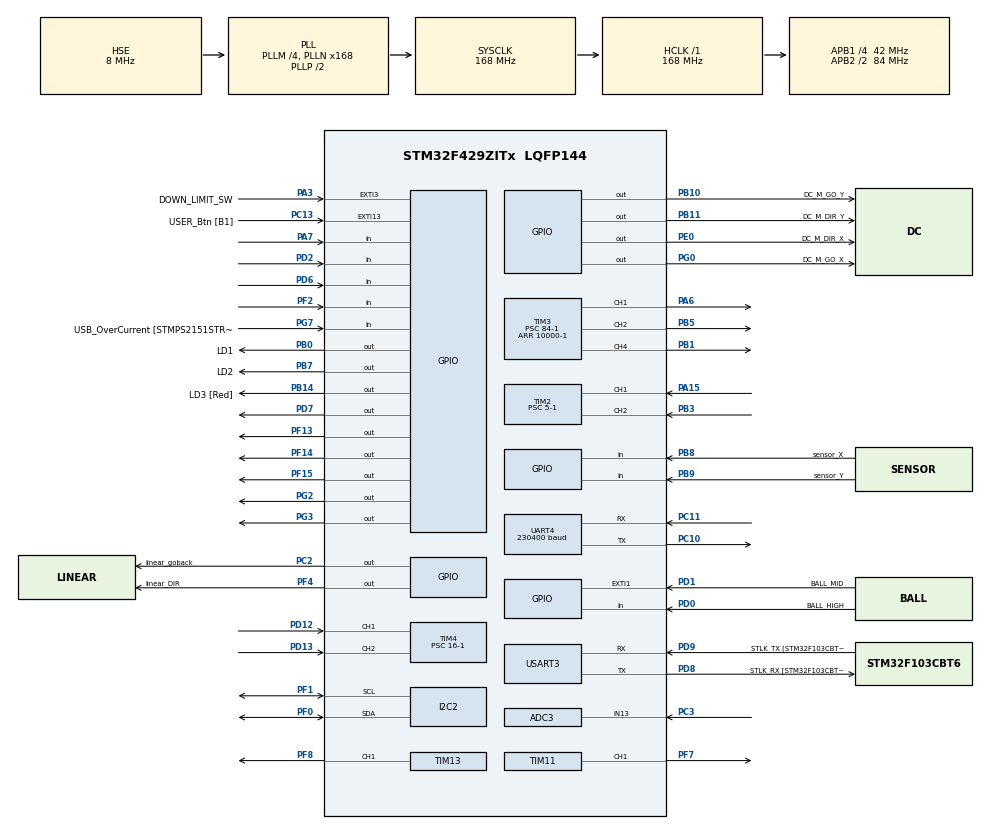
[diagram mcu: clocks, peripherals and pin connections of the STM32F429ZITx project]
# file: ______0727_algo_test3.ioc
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ADC3.Channel-3\#ChannelRegularConversion=ADC_CHANNEL_13
ADC3.Channel-4\#ChannelRegularConversion=ADC_CHANNEL_10
ADC3.Channel-5\#ChannelRegularConversion=ADC_CHANNEL_11
ADC3.ContinuousConvMode=DISABLE
ADC3.DMAContinuousRequests=ENABLE
ADC3.DiscontinuousConvMode=ENABLE
ADC3.ExternalTrigConv=ADC_EXTERNALTRIGCONV_T8_TRGO
ADC3.NbrOfConversion=3
ADC3.NbrOfConversionFlag=1
ADC3.NbrOfDiscConversion=3
ADC3.Rank-3\#ChannelRegularConversion=1
ADC3.Rank-4\#ChannelRegularConversion=2
ADC3.Rank-5\#ChannelRegularConversion=3
ADC3.Resolution=ADC_RESOLUTION_12B
ADC3.SamplingTime-3\#ChannelRegularConversion=ADC_SAMPLETIME_480CYCLES
ADC3.SamplingTime-4\#ChannelRegularConversion=ADC_SAMPLETIME_480CYCLES
ADC3.SamplingTime-5\#ChannelRegularConversion=ADC_SAMPLETIME_480CYCLES
ADC3.ScanConvMode=ENABLE
Dma.ADC3.0.Direction=DMA_PERIPH_TO_MEMORY
Dma.ADC3.0.FIFOMode=DMA_FIFOMODE_DISABLE
Dma.ADC3.0.Instance=DMA2_Stream1
Dma.ADC3.0.MemDataAlignment=DMA_MDATAALIGN_HALFWORD
Dma.ADC3.0.MemInc=DMA_MINC_ENABLE
Dma.ADC3.0.Mode=DMA_CIRCULAR
Dma.ADC3.0.PeriphDataAlignment=DMA_PDATAALIGN_HALFWORD
Dma.ADC3.0.PeriphInc=DMA_PINC_DISABLE
Dma.ADC3.0.Priority=DMA_PRIORITY_LOW
Dma.Request0=ADC3
Mcu.Family=STM32F4
Mcu.Name=STM32F429ZITx
Mcu.Package=LQFP144
NVIC.ADC_IRQn=true\:14\:0\:true\:false\:true\:true\:true\:true
NVIC.DMA2_Stream1_IRQn=true\:0\:0\:false\:false\:true\:false\:true\:true
NVIC.EXTI15_10_IRQn=true\:0\:0\:false\:false\:true\:true\:true\:true
NVIC.EXTI1_IRQn=true\:2\:0\:true\:false\:true\:true\:true\:true
NVIC.EXTI3_IRQn=true\:0\:0\:false\:true\:true\:1\:true\:true\:true
NVIC.PriorityGroup=NVIC_PRIORITYGROUP_4
NVIC.TIM1_BRK_TIM9_IRQn=true\:0\:0\:true\:false\:true\:true\:true\:true
NVIC.TIM1_TRG_COM_TIM11_IRQn=true\:0\:0\:true\:false\:true\:true\:true\:true
NVIC.TIM1_UP_TIM10_IRQn=true\:0\:0\:true\:false\:true\:true\:true\:true
NVIC.TIM5_IRQn=true\:0\:0\:true\:false\:true\:true\:true\:true
NVIC.TIM6_DAC_IRQn=true\:0\:0\:true\:false\:true\:true\:true\:true
NVIC.TIM7_IRQn=true\:0\:0\:true\:false\:true\:true\:true\:true
NVIC.TIM8_BRK_TIM12_IRQn=true\:0\:0\:true\:false\:true\:true\:true\:true
NVIC.TIM8_TRG_COM_TIM14_IRQn=true\:0\:0\:true\:false\:true\:true\:true\:true
NVIC.TIM8_UP_TIM13_IRQn=true\:0\:0\:true\:false\:true\:true\:true\:true
NVIC.UART4_IRQn=true\:15\:0\:true\:false\:true\:true\:true\:true
NVIC.USART3_IRQn=true\:15\:0\:true\:false\:true\:true\:true\:true
PA13.GPIO_Label=TMS
PA13.Mode=Serial_Wire
PA13.Signal=SYS_JTMS-SWDIO
PA14.GPIO_Label=TCK
PA14.Mode=Serial_Wire
PA14.Signal=SYS_JTCK-SWCLK
PA15.GPIO_Speed=GPIO_SPEED_FREQ_VERY_HIGH
PA15.Signal=S_TIM2_CH1_ETR
PA3.GPIO_Label=DOWN_LIMIT_SW
PA3.GPIO_ModeDefaultEXTI=GPIO_MODE_IT_FALLING
PA3.Signal=GPXTI3
PA6.GPIO_Speed=GPIO_SPEED_FREQ_VERY_HIGH
PA6.Signal=S_TIM3_CH1
PA7.Signal=GPIO_Input
PB0.GPIO_Label=LD1
PB0.Signal=GPIO_Output
PB1.GPIO_Speed=GPIO_SPEED_FREQ_VERY_HIGH
PB1.Signal=S_TIM3_CH4
PB10.GPIO_Label=DC_M_GO_Y
PB10.GPIO_Speed=GPIO_SPEED_FREQ_LOW
PB10.Signal=GPIO_Output
PB11.GPIO_Label=DC_M_DIR_Y
PB11.GPIO_Speed=GPIO_SPEED_FREQ_VERY_HIGH
PB11.Signal=GPIO_Output
PB14.GPIO_Label=LD3 [Red]
PB14.Signal=GPIO_Output
PB3.GPIO_Speed=GPIO_SPEED_FREQ_VERY_HIGH
PB3.Signal=S_TIM2_CH2
PB5.GPIO_Speed=GPIO_SPEED_FREQ_VERY_HIGH
PB5.Signal=S_TIM3_CH2
PB7.GPIO_Label=LD2
PB7.Signal=GPIO_Output
PB8.GPIO_Label=sensor_X
PB8.Signal=GPIO_Input
PB9.GPIO_Label=sensor_Y
PB9.Signal=GPIO_Input
PC10.Mode=Asynchronous
PC10.Signal=UART4_TX
PC11.Mode=Asynchronous
PC11.Signal=UART4_RX
PC13.GPIO_Label=USER_Btn [B1]
PC13.Signal=GPXTI13
PC14/OSC32_IN.Mode=LSE-External-Oscillator
PC14/OSC32_IN.Signal=RCC_OSC32_IN
PC15/OSC32_OUT.Mode=LSE-External-Oscillator
PC15/OSC32_OUT.Signal=RCC_OSC32_OUT
PC2.GPIO_Label=linear_goback
PC2.Signal=GPIO_Output
PC3.Signal=ADCx_IN13
PD0.GPIO_Label=BALL_HIGH
PD0.Signal=GPIO_Input
PD1.GPIO_Label=BALL_MID
PD1.GPIO_ModeDefaultEXTI=GPIO_MODE_IT_FALLING
PD1.Signal=GPXTI1
PD12.GPIO_Speed=GPIO_SPEED_FREQ_VERY_HIGH
PD12.Signal=S_TIM4_CH1
PD13.GPIO_Speed=GPIO_SPEED_FREQ_VERY_HIGH
PD13.Signal=S_TIM4_CH2
PD2.Signal=GPIO_Input
PD6.Signal=GPIO_Input
PD7.Signal=GPIO_Output
PD8.GPIO_Label=STLK_RX [STM32F103CBT6_PA3]
PD8.Mode=Asynchronous
PD8.Signal=USART3_TX
PD9.GPIO_Label=STLK_TX [STM32F103CBT6_PA2]
PD9.Mode=Asynchronous
PD9.Signal=USART3_RX
PE0.GPIO_Label=DC_M_DIR_X
PE0.GPIO_Speed=GPIO_SPEED_FREQ_VERY_HIGH
PE0.Signal=GPIO_Output
PF0.Mode=I2C
PF0.Signal=I2C2_SDA
PF1.Mode=I2C
PF1.Signal=I2C2_SCL
PF13.Signal=GPIO_Output
PF14.Signal=GPIO_Output
PF15.Signal=GPIO_Output
PF2.Signal=GPIO_Input
PF4.GPIO_Label=linear_DIR
PF4.Signal=GPIO_Output
PF7.GPIO_Speed=GPIO_SPEED_FREQ_VERY_HIGH
PF7.Signal=S_TIM11_CH1
PF8.GPIO_Speed=GPIO_SPEED_FREQ_VERY_HIGH
PF8.Signal=S_TIM13_CH1
PG0.GPIO_Label=DC_M_GO_X
PG0.GPIO_Speed=GPIO_SPEED_FREQ_LOW
PG0.Signal=GPIO_Output
PG2.Signal=GPIO_Output
PG3.Signal=GPIO_Output
PG7.GPIO_Label=USB_OverCurrent [STMPS2151STR_FAULT]
PG7.Signal=GPIO_Input
PH0/OSC_IN.GPIO_Label=MCO [STM32F103CBT6_PA8]
PH0/OSC_IN.Mode=HSE-External-Clock-Source
PH0/OSC_IN.Signal=RCC_OSC_IN
PH1/OSC_OUT.Mode=HSE-External-Clock-Source
PH1/OSC_OUT.Signal=RCC_OSC_OUT
ProjectManager.HeapSize=0x200
ProjectManager.StackSize=0x400
ProjectManager.TargetToolchain=STM32CubeIDE
RCC.48MHZClocksFreq_Value=48000000
RCC.AHBFreq_Value=168000000
RCC.APB1CLKDivider=RCC_HCLK_DIV4
RCC.APB1Freq_Value=42000000
RCC.APB1TimFreq_Value=84000000
RCC.APB2CLKDivider=RCC_HCLK_DIV2
RCC.APB2Freq_Value=84000000
RCC.APB2TimCLKDivider=2
RCC.APB2TimFreq_Value=168000000
RCC.CortexFreq_Value=168000000
RCC.HCLKFreq_Value=168000000
RCC.HSE_VALUE=8000000
RCC.HSI_VALUE=16000000
RCC.PLLM=4
RCC.PLLMUL=RCC_PLL_MUL9
RCC.PLLN=168
RCC.PLLQ=7
RCC.PLLSourceVirtual=RCC_PLLSOURCE_HSE
RCC.PRESCALERUSB=RCC_USBCLKSOURCE_PLL_DIV1_5
RCC.SYSCLKFreq_VALUE=168000000
RCC.SYSCLKSource=RCC_SYSCLKSOURCE_PLLCLK
RCC.SYSCLKSourceVirtual=RCC_SYSCLKSOURCE_PLLCLK
RCC.USBFreq_Value=48000000
RCC.VCOOutputFreq_Value=336000000
SH.ADCx_IN13.0=ADC3_IN13,IN13
SH.S_TIM11_CH1.0=TIM11_CH1,Output Compare1 CH1
SH.S_TIM13_CH1.0=TIM13_CH1,Output Compare1 CH1
SH.S_TIM2_CH1_ETR.0=TIM2_CH1,Encoder_Interface
SH.S_TIM2_CH2.0=TIM2_CH2,Encoder_Interface
SH.S_TIM3_CH1.0=TIM3_CH1,PWM Generation1 CH1
SH.S_TIM3_CH2.0=TIM3_CH2,PWM Generation2 CH2
SH.S_TIM3_CH4.0=TIM3_CH4,PWM Generation4 CH4
SH.S_TIM4_CH1.0=TIM4_CH1,Encoder_Interface
SH.S_TIM4_CH2.0=TIM4_CH2,Encoder_Interface
TIM10.Period=1000-1
TIM10.Prescaler=16800-1
TIM11.AutoReloadPreload=TIM_AUTORELOAD_PRELOAD_ENABLE
TIM11.Channel=TIM_CHANNEL_1
TIM11.OCMode_1=TIM_OCMODE_TOGGLE
TIM11.Period=800-1
TIM11.Prescaler=168-1
TIM11.Pulse=50
TIM12.Period=1000-1
TIM12.Prescaler=8400-1
TIM13.AutoReloadPreload=TIM_AUTORELOAD_PRELOAD_ENABLE
TIM13.Channel=TIM_CHANNEL_1
TIM13.OC1Preload=ENABLE
TIM13.OCMode_1=TIM_OCMODE_TOGGLE
TIM13.Period=800-1
TIM13.Prescaler=84-1
TIM13.Pulse=130
TIM14.Period=10000-1
TIM14.Prescaler=84-1
TIM2.EncoderMode=TIM_ENCODERMODE_TI12
TIM2.Period=0xffffffff
TIM2.Prescaler=5-1
TIM3.Channel-PWM\ Generation1\ CH1=TIM_CHANNEL_1
TIM3.Channel-PWM\ Generation2\ CH2=TIM_CHANNEL_2
TIM3.Channel-PWM\ Generation4\ CH4=TIM_CHANNEL_4
TIM3.Period=10000-1
TIM3.Prescaler=84-1
TIM3.Pulse-PWM\ Generation1\ CH1=600
TIM3.Pulse-PWM\ Generation2\ CH2=600
TIM3.Pulse-PWM\ Generation4\ CH4=0
TIM4.EncoderMode=TIM_ENCODERMODE_TI12
TIM4.Period=0xFFFF-1
TIM4.Prescaler=16-1
TIM5.Period=10000-1
TIM5.Prescaler=84-1
TIM6.Period=1000-1
TIM6.Prescaler=84-1
TIM7.Period=100-1
TIM7.Prescaler=84-1
TIM8.Channel-Output\ Compare4\ No\ Output=TIM_CHANNEL_4
TIM8.Period=300-1
TIM8.Prescaler=84-1
TIM8.Pulse-Output\ Compare4\ No\ Output=2000
TIM8.TIM_MasterOutputTrigger=TIM_TRGO_UPDATE
TIM9.Period=1000-1
TIM9.Prescaler=16800-1
UART4.BaudRate=230400
UART4.Parity=PARITY_EVEN
UART4.VirtualMode=Asynchronous
USART3.VirtualMode=VM_ASYNC
VP_TIM10_VS_ClockSourceINT.Mode=Enable_Timer
VP_TIM11_VS_ClockSourceINT.Mode=Enable_Timer
VP_TIM12_VS_ClockSourceINT.Mode=Internal
VP_TIM13_VS_ClockSourceINT.Mode=Enable_Timer
VP_TIM14_VS_ClockSourceINT.Mode=Enable_Timer
VP_TIM3_VS_ClockSourceINT.Mode=Internal
VP_TIM5_VS_ClockSourceINT.Mode=Internal
VP_TIM6_VS_ClockSourceINT.Mode=Enable_Timer
VP_TIM7_VS_ClockSourceINT.Mode=Enable_Timer
VP_TIM8_VS_ClockSourceINT.Mode=Internal
VP_TIM8_VS_no_output4.Mode=Output Compare4 No Output
VP_TIM9_VS_ClockSourceINT.Mode=Internal
board=NUCLEO-F429ZI

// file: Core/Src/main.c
/* USER CODE BEGIN Header */
/**
 ******************************************************************************
 * @file           : main.c
 * @brief          : Main program body
 ******************************************************************************
 * @attention
 *
 * Copyright (c) 2024 STMicroelectronics.
 * All rights reserved.
 *
 * This software is licensed under terms that can be found in the LICENSE file
 * in the root directory of this software component.
 * If no LICENSE file comes with this software, it is provided AS-IS.
 *
 ******************************************************************************
 */
/* USER CODE END Header */
#include "main.h"

/* USER CODE BEGIN Includes */
#include "pid.h"
#include "sensor.h"
#include "step.h"
#include "linear.h"
#include "pp.h"
#include "mpu6050.h"
#include "queue.h"
//시뮬링크
#include "rtwtypes.h"
#include "downpart_accel.h"
//

uint8_t key_value;

uint8_t data;

uint32_t encoder_count_x = 1000000;
uint16_t encoder_count_y = 30000;
extern uint32_t tim4_encoder_overflow;

uint16_t ADC3_value[3];

extern uint8_t tim6_flag;
extern uint8_t tim14_flag;
extern uint8_t tim5_flag;
/* USER CODE END Includes */

/* USER CODE BEGIN PM */
extern uint16_t shaft_pulse_cycle;
extern uint16_t ball_screw_pulse_cycle;
/* USER CODE END PM */

ADC_HandleTypeDef hadc3;
DMA_HandleTypeDef hdma_adc3;

I2C_HandleTypeDef hi2c2;

TIM_HandleTypeDef htim2;
TIM_HandleTypeDef htim3;
TIM_HandleTypeDef htim4;
TIM_HandleTypeDef htim5;
TIM_HandleTypeDef htim6;
TIM_HandleTypeDef htim7;
TIM_HandleTypeDef htim8;
TIM_HandleTypeDef htim9;
TIM_HandleTypeDef htim10;
TIM_HandleTypeDef htim11;
TIM_HandleTypeDef htim12;
TIM_HandleTypeDef htim13;
TIM_HandleTypeDef htim14;

UART_HandleTypeDef huart4;
UART_HandleTypeDef huart3;

void SystemClock_Config(void);
static void MX_GPIO_Init(void);
static void MX_DMA_Init(void);
static void MX_USART3_UART_Init(void);
static void MX_TIM3_Init(void);
static void MX_TIM14_Init(void);
static void MX_UART4_Init(void);
static void MX_TIM2_Init(void);
static void MX_TIM8_Init(void);
static void MX_TIM6_Init(void);
static void MX_TIM13_Init(void);
static void MX_ADC3_Init(void);
static void MX_TIM12_Init(void);
static void MX_TIM11_Init(void);
static void MX_TIM4_Init(void);
static void MX_TIM7_Init(void);
static void MX_TIM5_Init(void);
static void MX_I2C2_Init(void);
static void MX_TIM9_Init(void);
static void MX_TIM10_Init(void);
static void MX_NVIC_Init(void);
/* USER CODE BEGIN PFP */
bool accel_flag;

//struct {
//	bool target_2_1;
//	bool target_3_1;
//	bool target_1_2;
//	bool target_2_2;
//	bool target_3_2;
//
//	bool box_pickup;
//	bool Box_dropoff;
//} Manual_mode = { FALSE, FALSE, FALSE };
struct Manual Manual_mode = { FALSE, FALSE, FALSE, FALSE, FALSE, FALSE, FALSE};

struct flag Finish_flag = { FALSE, FALSE, FALSE, FALSE, FALSE, FALSE, FALSE, 0,
		0, FALSE, FALSE };

float targetS_X_GO = 53;
float targetS_X_BACK = 56.0;

float targetS_Y_GO = 49;
float targetS_Y_BACK = 48;

float targetS_X_GO2 = 98;
float targetS_X_BACK2 = 103;
//

float go_time = 1.25;
float back_time = 1.4;

/* USER CODE END PFP */

/* USER CODE BEGIN 0 */
bool photo_X_go = FALSE;
bool photo_X_back = FALSE;
bool photo_Y_go = FALSE;
bool photo_Y_back = FALSE;

int pickup_run;
int dropoff_run;

extern int pathLength;

cell path[CELL_DOMAIN_MAX];

extern float maxV;
extern float fallingN;
extern float fallingN_;
extern float raisingN;
extern float staticN;
extern float orderN;
extern uint16_t i_v_t_count;

uint8_t target_1_2_flag = 0;
uint8_t target_2_1_flag = 0;
uint8_t target_3_1_flag = 0;
uint8_t target_2_2_flag = 0;
uint8_t target_3_2_flag = 0;
uint8_t box_pickup_flag = 0;
uint8_t box_dropoff_flag = 0;
void FALSE_Init() {
	Finish_flag.x_go = FALSE;
	Finish_flag.x_back = FALSE;
	Finish_flag.y_go = FALSE;
	Finish_flag.y_back = FALSE;
	Finish_flag.ball_high = FALSE;
	Finish_flag.ball_mid = FALSE;
	Finish_flag.ball_low = FALSE;
	Finish_flag.downpart_high = FALSE;
	Finish_flag.downpart_low = FALSE;
	Finish_flag.linear_go = FALSE;
	Finish_flag.linear_back = FALSE;

	target_1_2_flag = 0;
	target_2_1_flag = 0;
	target_3_1_flag = 0;
	target_2_2_flag = 0;
	target_3_2_flag = 0;
	box_pickup_flag = 0;
	box_dropoff_flag = 0;

	pickup_run=0;
	dropoff_run= 0;
	Manual_mode.box_pickup = FALSE;
	Manual_mode.Box_dropoff = FALSE;
}
uint32_t downpart_step_1_floor = 8100; //
uint32_t downpart_step_2_floor = 6600;
uint32_t downpart_step_3_floor = 4500;  //예상
uint8_t box_floor;

int box_floor_test_pick = 1;
int box_floor_test_drop = 1;

//박스 적재 동작 : 다운파트 하강, 리니어 전진, 다운파트 상승

uint8_t box_floor;  //테스트용도
uint32_t downpart_step_floor;

void Box_pickup(uint8_t floor) {
	HAL_TIM_Encoder_Stop(&htim2, TIM_CHANNEL_ALL);
	HAL_TIM_Encoder_Stop(&htim4, TIM_CHANNEL_ALL);

	HAL_TIM_PWM_Stop(&htim3, TIM_CHANNEL_1);
	HAL_TIM_PWM_Stop(&htim3, TIM_CHANNEL_2);

	TIM3->CCR1 = 0;
	TIM3->CCR2 = 0;
	pickup_run = 1;

	box_floor = floor;

	if (floor == 1)
		downpart_step_floor = downpart_step_1_floor;
	else if (floor == 2)
		downpart_step_floor = downpart_step_2_floor;
	else if (floor == 3)
		downpart_step_floor = downpart_step_3_floor;

//	if (Manual_mode.box_pickup == TRUE) {
	if (box_pickup_flag == 0) {

		down_part_DOWN_accel(downpart_step_floor);
		box_pickup_flag = 1;
	}

	if ((Finish_flag.downpart_low == TRUE) && (box_pickup_flag == 1)) {
		box_pickup_flag = 2;
		HAL_Delay(700 - 1);

		linear_motor_GO(go_time);
		Finish_flag.downpart_low = FALSE;
	}
	if ((Finish_flag.linear_go == TRUE) && (box_pickup_flag == 2)) {
		box_pickup_flag = 3;
		HAL_Delay(700 - 1);
		down_part_UP_accel(downpart_step_floor + 10000);
		Finish_flag.linear_go = FALSE;
	}
	if ((Finish_flag.downpart_high == TRUE) && (box_pickup_flag == 3)) {
		box_pickup_flag = 4;
		HAL_Delay(120 - 1);

		down_part_DOWN(130, shaft_pulse_cycle);
		Finish_flag.downpart_high = FALSE;
	}
	if(	Finish_flag.downpart_low == TRUE && box_pickup_flag ==4)
	{
		box_pickup_flag =5;
		HAL_Delay(700 - 1);
		Finish_flag.downpart_low = FALSE;
		Manual_mode.box_pickup = FALSE;
		pickup_run = 0;
	}
//	}
}

//박스 하역 동작 : 다운파트 하강, 리니어 후진, 다운파트 상승
void Box_dropoff(uint8_t floor) {
	HAL_TIM_Encoder_Stop(&htim2, TIM_CHANNEL_ALL);
	HAL_TIM_Encoder_Stop(&htim4, TIM_CHANNEL_ALL);

	HAL_TIM_PWM_Stop(&htim3, TIM_CHANNEL_1);
	HAL_TIM_PWM_Stop(&htim3, TIM_CHANNEL_2);

	TIM3->CCR1 = 0;
	TIM3->CCR2 = 0;

	dropoff_run = 1;

	box_floor = floor;

	if (floor == 1)
		downpart_step_floor = downpart_step_1_floor;
	else if (floor == 2)
		downpart_step_floor = downpart_step_2_floor;
	else if (floor == 3)
		downpart_step_floor = downpart_step_3_floor;

	//if (Manual_mode.Box_dropoff == TRUE) {
	if (box_dropoff_flag == 0) {
		down_part_DOWN_accel(downpart_step_floor);
		box_dropoff_flag = 1;
	}

	if ((Finish_flag.downpart_low == TRUE) && (box_dropoff_flag == 1)) {
		box_dropoff_flag = 2;
		HAL_Delay(700 - 1);

		linear_motor_BACK(back_time);
		Finish_flag.downpart_low = FALSE;
	}
	if ((Finish_flag.linear_back == TRUE) && (box_dropoff_flag == 2)) {
		box_dropoff_flag = 3;
		HAL_Delay(200 - 1);
		down_part_UP_accel(downpart_step_floor + 10000);
		Finish_flag.linear_back = FALSE;
	}
	if ((Finish_flag.downpart_high == TRUE) && (box_dropoff_flag == 3)) {
		box_dropoff_flag = 4;
		HAL_Delay(120 - 1);

		down_part_DOWN(130, shaft_pulse_cycle);
		Finish_flag.downpart_high = FALSE;
	}
	if(Finish_flag.downpart_low == TRUE && (box_dropoff_flag == 4))
	{
		box_dropoff_flag =5;
		HAL_Delay(700 - 1);
		Finish_flag.downpart_low = FALSE;
		Manual_mode.Box_dropoff = FALSE;
		dropoff_run = 0;
	}

//	}
}

//y축 1칸 왕복,  볼스크류 왕복  다운파트 통합본					                                     			1              2           3                         4              5                       6
void Manual_Mode_Y1(float row, float col, uint8_t floor_pick,
		uint8_t floor_drop) { //볼스크류 하상 먼저 >> y 전진, 다운파트 하강, 리니어 전진, 다운파트 상승, y 후진, 다운파트 하강, 리니어 후진 ,다운파트 상승, 볼스크류 상승
//																	      -------------------------------        ------------------------------
	if (Manual_mode.target_1_2 == TRUE) {

		if (target_1_2_flag == 0) {

			z_axis_DOWN(400 * 6 * 2 + 500, ball_screw_pulse_cycle);
			target_1_2_flag = 1;
		}

		if ((Finish_flag.ball_low == TRUE) && (target_1_2_flag == 1)) {
			target_1_2_flag = 2;
			HAL_Delay(700 - 1);
			v_t_graph_DIR_GO_Y(targetS_Y_GO);  //앞으로

			Finish_flag.ball_low = FALSE;
		}
		if ((Finish_flag.y_go == TRUE) && (target_1_2_flag == 2)) {
			target_1_2_flag = 3;
			HAL_Delay(2100 - 1);

			Manual_mode.box_pickup = TRUE;
			box_floor_test_pick = floor_pick;
			Finish_flag.y_go = FALSE;
		}
		if ((Manual_mode.box_pickup == FALSE) && (target_1_2_flag == 3)) {

			target_1_2_flag = 4;
			HAL_Delay(700 - 1);
			v_t_graph_DIR_BACK_Y(targetS_Y_BACK);

		}
		if ((Finish_flag.y_back == TRUE) && (target_1_2_flag == 4)) {
			target_1_2_flag = 5;
			HAL_Delay(700 - 1);
			//		down_part_DOWN_accel(downpart_step_1_floor);

			Manual_mode.Box_dropoff = TRUE;
			box_floor_test_drop = floor_drop;

			Finish_flag.y_back = FALSE;
		}

		if ((Manual_mode.Box_dropoff == FALSE) && (target_1_2_flag == 5)) {

			target_1_2_flag = 6;

			HAL_Delay(900 - 1);
			z_axis_UP(400 * 6 * 2, ball_screw_pulse_cycle);

			FALSE_Init();
			Manual_mode.target_1_2 = FALSE;
		}
	}
}

//(2,1)  (3,1)    여기는 볼스크류 필요없음                         //1       2          3            4       5        6          7        8
void Manual_Mode_X1(float row, float col, uint8_t floor_pick,
		uint8_t floor_drop) { // x전진 , 다운파트 하강, 리니어 전진, 다운파트 상승, x후진, 다운파트 하강, 리니어 후진, 다운파트 상승 끝
	//				                 -----------------------------          ----------------------------
	if (Manual_mode.target_2_1 == TRUE) {

		if (target_2_1_flag == 0) {
			v_t_graph_DIR_GO_X(targetS_X_GO);  //앞으로

			target_2_1_flag = 1;
		}

		if ((Finish_flag.x_go == TRUE) && (target_2_1_flag == 1)) {
			target_2_1_flag = 2;
			HAL_Delay(2100 - 1);

			Manual_mode.box_pickup = TRUE;
			box_floor_test_pick = floor_pick;
			Finish_flag.x_go = FALSE;

		}

		if ((Manual_mode.box_pickup == FALSE) && (target_2_1_flag == 2)) {

			target_2_1_flag = 3;
			HAL_Delay(700 - 1);
			v_t_graph_DIR_BACK_X(targetS_X_BACK);

		}
		if ((Finish_flag.x_back == TRUE) && (target_2_1_flag == 3)) {
			target_2_1_flag = 4;
			HAL_Delay(700 - 1);

			Manual_mode.Box_dropoff = TRUE;
			box_floor_test_drop = floor_drop;

			Finish_flag.x_back = FALSE;
		}

		if ((Manual_mode.Box_dropoff == FALSE) && (target_2_1_flag == 4)) {
			target_2_1_flag = 5;

			FALSE_Init();
			Manual_mode.target_2_1 = FALSE;
		}
	}
}

//			 1                    2                   3              4
void Manual_Mode_X2(float row, float col, uint8_t floor_pick,
		uint8_t floor_drop) { // x전진 , 다운파트 하강, 리니어 전진, 다운파트 상승, x후진, 다운파트 하강, 리니어 후진, 다운파트 상승 끝
	//				                                                   -----------------------------          ----------------------------
	if (Manual_mode.target_3_1 == TRUE) {

		if (target_3_1_flag == 0) {
			v_t_graph_DIR_GO_X(targetS_X_GO2);  //앞으로

			target_3_1_flag = 1;
		}

		if ((Finish_flag.x_go == TRUE) && (target_3_1_flag == 1)) {
			target_3_1_flag = 2;
			HAL_Delay(2100 - 1);

			Manual_mode.box_pickup = TRUE;
			box_floor_test_pick = floor_pick;
			Finish_flag.x_go = FALSE;

		}

		if ((Manual_mode.box_pickup == FALSE) && (target_3_1_flag == 2)) {

			target_3_1_flag = 3;
			HAL_Delay(700 - 1);
			v_t_graph_DIR_BACK_X(targetS_X_BACK2);

		}
		if ((Finish_flag.x_back == TRUE) && (target_3_1_flag == 3)) {
			target_3_1_flag = 4;
			HAL_Delay(700 - 1);

			Manual_mode.Box_dropoff = TRUE;
			box_floor_test_drop = floor_drop;

			Finish_flag.x_back = FALSE;
		}

		if ((Manual_mode.Box_dropoff == FALSE) && (target_3_1_flag == 4)) {
			target_3_1_flag = 5;

			FALSE_Init();
			Manual_mode.target_3_1 = FALSE;
		}
	}
}

// x축 1칸 전진 ,볼스크류 2번 다운, y축 전진 , y축 후진 , 볼스크류 2번 업, x축 후진
//여기서 다운 파트 추가
//x 1칸 전진 , 볼스크류 다운, y축 전진 , 다운파트 하강, 리니어 전진, 다운파트 상승, y후진, 볼스크류 업, x후진, 다운파트 하상, 리니어 후진, 다운파트 상승
//                               ------------------------------                      --------------------------------
// 1              2         3                  4                    5       6     7          8
void Manual_Mode_X1Y1(float row, float col, uint8_t floor_pick,
		uint8_t floor_drop) {

	if (Manual_mode.target_2_2 == TRUE) {

		if (target_2_2_flag == 0) {
			v_t_graph_DIR_GO_X(targetS_X_GO);  // x 앞으로

			target_2_2_flag = 1;
		}

		if ((Finish_flag.x_go == TRUE) && (target_2_2_flag == 1)) {
			target_2_2_flag = 2;
			HAL_Delay(700 - 1);

			z_axis_DOWN(400 * 6 * 2 + 500, ball_screw_pulse_cycle); //볼스크류 2번 다운

			Finish_flag.x_go = FALSE;
		}
		if ((Finish_flag.ball_low == TRUE) && (target_2_2_flag == 2)) {
			target_2_2_flag = 3;
			HAL_Delay(700 - 1);
			v_t_graph_DIR_GO_Y(targetS_Y_GO); //					// y축 전진
			Finish_flag.ball_low = FALSE;
		}
		if ((Finish_flag.y_go == TRUE) && (target_2_2_flag == 3)) {
			target_2_2_flag = 4;
			HAL_Delay(3000 - 1);

			Manual_mode.box_pickup = TRUE;
			box_floor_test_pick = floor_pick;

			Finish_flag.y_go = FALSE;
		}
		if ((Manual_mode.box_pickup == FALSE) && (target_2_2_flag == 4)) {
			target_2_2_flag = 5;
			HAL_Delay(700 - 1);
			v_t_graph_DIR_BACK_Y(targetS_Y_BACK); //	y후진

			//Finish_flag.y_back = FALSE;
		}
		if ((Finish_flag.y_back == TRUE) && (target_2_2_flag == 5)) {
			target_2_2_flag = 6;
			HAL_Delay(700 - 1);

			z_axis_UP(400 * 6 * 2, ball_screw_pulse_cycle); //		    볼스크류 2번 업

			Finish_flag.y_back = FALSE;
		}
		if ((Finish_flag.ball_high == TRUE) && (target_2_2_flag == 6)) {
			target_2_2_flag = 7;
			HAL_Delay(700 - 1);
			v_t_graph_DIR_BACK_X(targetS_X_BACK); //
			Finish_flag.ball_high = FALSE;
		}
		if ((Finish_flag.x_back == TRUE) && (target_2_2_flag == 7)) {
			target_2_2_flag = 8;
			HAL_Delay(700 - 1);

			Manual_mode.Box_dropoff = TRUE;
			box_floor_test_drop = floor_drop;

			Finish_flag.x_back = FALSE;
		}
		if ((Manual_mode.Box_dropoff == FALSE) && (target_2_2_flag == 8)) {
			target_2_2_flag = 9;
			HAL_Delay(700 - 1);

			FALSE_Init();
			Manual_mode.target_2_2 = FALSE;
		}

	}
}

//x 1칸 전진 , 볼스크류 다운, y축 전진 , 다운파트 하강, 리니어 전진, 다운파트 상승, y후진, 볼스크류 업, x후진, 다운파트 하상, 리니어 후진, 다운파트 상승
//                               ------------------------------                      --------------------------------
// 1              2         3                  4                    5       6     7          8
void Manual_Mode_X2Y1(float row, float col, uint8_t floor_pick,
		uint8_t floor_drop) {

	if (Manual_mode.target_3_2 == TRUE) {

		if (target_3_2_flag == 0) {
			v_t_graph_DIR_GO_X(targetS_X_GO2);  // x 2칸 앞으로

			target_3_2_flag = 1;
		}

		if ((Finish_flag.x_go == TRUE) && (target_3_2_flag == 1)) {
			target_3_2_flag = 2;
			HAL_Delay(700 - 1);

			z_axis_DOWN(400 * 6 * 2 + 500, ball_screw_pulse_cycle); //볼스크류 2번 다운

			Finish_flag.x_go = FALSE;
		}
		if ((Finish_flag.ball_low == TRUE) && (target_3_2_flag == 2)) {
			target_3_2_flag = 3;
			HAL_Delay(700 - 1);
			v_t_graph_DIR_GO_Y(targetS_Y_GO); //					// y축 전진
			Finish_flag.ball_low = FALSE;
		}
		if ((Finish_flag.y_go == TRUE) && (target_3_2_flag == 3)) {
			target_3_2_flag = 4;
			HAL_Delay(2100 - 1);

			Manual_mode.box_pickup = TRUE;

			box_floor_test_pick = floor_pick;

			Finish_flag.y_go = FALSE;
		}
		if ((Manual_mode.box_pickup == FALSE) && (target_3_2_flag == 4)) {
			target_3_2_flag = 5;
			HAL_Delay(700 - 1);
			v_t_graph_DIR_BACK_Y(targetS_Y_BACK); //	y후진

			//Finish_flag.y_back = FALSE;
		}
		if ((Finish_flag.y_back == TRUE) && (target_3_2_flag == 5)) {
			target_3_2_flag = 6;
			HAL_Delay(700 - 1);

			z_axis_UP(400 * 6 * 2, ball_screw_pulse_cycle); //		    볼스크류 2번 업

			Finish_flag.y_back = FALSE;
		}
		if ((Finish_flag.ball_high == TRUE) && (target_3_2_flag == 6)) {
			target_3_2_flag = 7;
			HAL_Delay(700 - 1);
			v_t_graph_DIR_BACK_X(targetS_X_BACK2); //
			Finish_flag.ball_high = FALSE;
		}
		if ((Finish_flag.x_back == TRUE) && (target_3_2_flag == 7)) {
			target_3_2_flag = 8;
			HAL_Delay(700 - 1);

			Manual_mode.Box_dropoff = TRUE;
			box_floor_test_drop = floor_drop;

			Finish_flag.x_back = FALSE;
		}
		if ((Manual_mode.Box_dropoff == FALSE) && (target_3_2_flag == 8)) {
			target_3_2_flag = 9;
			HAL_Delay(700 - 1);

			FALSE_Init();
			Manual_mode.target_3_2 = FALSE;
		}

	}
}

int linear_init = 0;

char txData[] = "Hello, UART3!\r\n";
char rxData[100];

uint8_t rxByte;
volatile uint8_t rxIndex = 0;

#define DATA_SIZE 200

char segment[6];

char Rx_data[DATA_SIZE];
char Rx_buffer[2];  // 1글자씩 수신
int Transfer_finish = 0;  // 전송 완료 플래그

extern float RPM_X, RPM_Y;
extern int down_max_flag;

int plc;

int pik;

int rol = 0;

Queue str_q;
char pased_flag = '0';
char tmp;

bool paser_flag = FALSE;

void fillQueue(char *input) {
	int input_length = strlen(input);
	int i = 0;

	for (i = 0; i < input_length; i++) {
		enqueue(&str_q, input[i]);
	}
}
char cmd_[4];

char num;
/*
 void analyzer(char cmd[4], char num) {

 if (strcmp(&cmd[0], "mov") == 0) {
 //		mov++;

 HAL_Delay(2500);
 if (rol % 2==0)  //짝수: x방향  후진
 {
 if(num == '1')
 {
 v_t_graph_DIR_BACK_X(targetS_X_BACK);  // x 앞으로
 }
 else if(num == '2')
 {
 v_t_graph_DIR_BACK_X(targetS_X_BACK2);  // x 앞으로
 }
 }
 else if (rol % 2==1)  //홀수 y방향  후진
 {
 if(num == '1')
 {
 v_t_graph_DIR_BACK_Y(targetS_Y_BACK);
 }

 }

 } else if (strcmp(&cmd[0], "pov") == 0) {
 //		pov++;

 HAL_Delay(2500);
 if (rol % 2==0)  //짝수: x방향 전진
 {
 if(num == '1')
 {
 v_t_graph_DIR_GO_X(targetS_X_GO);  // x 앞으로
 }
 else if(num == '2')
 {
 v_t_graph_DIR_GO_X(targetS_X_GO2);  // x 앞으로
 }
 }
 else if (rol % 2==1)  //홀수 y방향  전진
 {
 if(num == '1')
 {
 v_t_graph_DIR_GO_Y(targetS_Y_GO);
 }

 }

 } else if (strcmp(&cmd[0], "rol") == 0) {

 HAL_Delay(2500);
 if(num == '0')
 {
 z_axis_DOWN(400 * 6 * 2+700, ball_screw_pulse_cycle);   //볼 내림 x -> y

 }
 else if(num == '1')
 {
 z_axis_UP(400 * 6 * 2, ball_screw_pulse_cycle);   //볼 올림 y -> x

 }
 rol++;

 } else if (strcmp(&cmd[0], "pik") == 0) {
 pik++;
 HAL_Delay(2500);
 if(num == '1')
 {
 FALSE_Init();

 Manual_mode.box_pickup = TRUE;
 box_floor_test_pick=1;
 }
 else if(num == '2')
 {
 FALSE_Init();

 Manual_mode.box_pickup = TRUE;
 box_floor_test_pick=2;
 }
 else if(num == '3')
 {
 FALSE_Init();

 Manual_mode.box_pickup = TRUE;
 box_floor_test_pick=3;
 }

 } else if (strcmp(&cmd[0], "plc") == 0) {
 plc++;
 HAL_Delay(2500);
 if(num == '1')
 {
 FALSE_Init();

 Manual_mode.Box_dropoff = TRUE;
 box_floor_test_drop=1;
 }
 else if(num == '2')
 {
 FALSE_Init();

 Manual_mode.Box_dropoff = TRUE;
 box_floor_test_drop=2;
 }
 else if(num == '3')
 {
 FALSE_Init();

 Manual_mode.Box_dropoff = TRUE;
 box_floor_test_drop=3;
 }

 }
 return;
 }
 */
AnalyzerType Analyzer = { FALSE, FALSE, FALSE, FALSE, FALSE, FALSE, FALSE,
		FALSE, FALSE, FALSE };

void analyzer(char cmd[4], char num_) {
	num = num_;

	if (strcmp(&cmd[0], "mov") == 0) {

		Analyzer.mov = TRUE;

	} else if (strcmp(&cmd[0], "pov") == 0) {

		Analyzer.pov = TRUE;

	} else if (strcmp(&cmd[0], "rol") == 0) {

		Analyzer.rol = TRUE;

	} else if (strcmp(&cmd[0], "pik") == 0) {

		Analyzer.pik = TRUE;

	} else if (strcmp(&cmd[0], "plc") == 0) {

		Analyzer.plc = TRUE;

	}
	return;
}

void paser(char *input) {
	if (pased_flag == '0') {
		//printf("start Queue\n");
		if (is_empty(&str_q)) {
			printf("queue is empty\n");
			return;
		}
		tmp = dequeue(&str_q);
		while (tmp != '@') {
			if (is_empty(&str_q)) {
				printf("queue is empty\n");
				return;
			}
			tmp = dequeue(&str_q);
		}
		pased_flag = '1';
	}

	if (tmp == '@' || tmp == '#') {
		char cmd[4] = "   \0";
		char num;

		int i = 0;
		for (i = 0; i < 3; i++) {
			cmd[i] = dequeue(&str_q);
		}

		dequeue(&str_q);
		num = dequeue(&str_q);
		tmp = dequeue(&str_q);

		analyzer(cmd, num);
		//	paser_flag=0;
	} else if (tmp == '!') {
		printf("needed new commend\n");
		pased_flag = '0';
	}
	return;
}

int countCmd(char *input) {
	int len = strlen(input);
	int cmdLen = 0;
	int i = 0;

	for (i = 0; i < len; i++) {
		if (input[i] == '@') {
			cmdLen = 0;
		} else {
			cmdLen++;
		}
		if (input[i] == '!') {
			return cmdLen / 6;
		}
	}
}

int count____;

char *input;

int down_high_test;
int ball_min_test;
int x_go;
int x_back;

int y_go;
int y_back;
int ball_high;

int RPM_X_go;
int RPM_X_back;
int RPM_Y_go;
int RPM_Y_back;
int PID_Y_finish;
int PID_X_finish;

// int downpart_run;
int ballscrew_up_run;

int ballscrew_down_run;
uint8_t step_count_for_flag__;

uint8_t shaft_accel_flag; //0:등속 ,1 가속

int DC_Y_go_sensor_flag;
int DC_Y_back_sensor_flag;

// int DC_X_now_posiotion;
int DC_Y_now_posiotion;

extern uint32_t save_X_IN;
extern uint32_t save_Y_IN;

uint16_t tim9_flag = 0;
uint16_t tim10_flag = 100;
bool tim12_flag = FALSE;

int asda = 0;

bool down_max_flag_ = FALSE;

int algo_y_go=0;
int algo_y_back=0;
int algo_x_go=0;
int algo_x_back=0;
int algo_x_go2=0;
int algo_x_back2=0;
int algo_rol_up=0;
int algo_rol_down=0;
int algo_pik1=0;
int algo_pik2=0;
int algo_pik3=0;
int algo_plc1=0;
int algo_plc2=0;
int algo_plc3=0;

bool algo_y_go_=FALSE;
bool algo_y_back_=FALSE;

char RxRX;
/* USER CODE END 0 */

int main(void)
{

  /* USER CODE BEGIN 1 */

	downpart_accel_initialize();

  /* USER CODE END 1 */

  /* MCU Configuration--------------------------------------------------------*/

  /* Reset of all peripherals, Initializes the Flash interface and the Systick. */
  HAL_Init();

  /* Configure the system clock */
  SystemClock_Config();

  /* USER CODE BEGIN SysInit */
	linear_init = 1;
	if (linear_init == 1) {
		HAL_GPIO_WritePin(GPIOF, GPIO_PIN_4, 1); //정지
	}
  /* USER CODE END SysInit */

  /* Initialize all configured peripherals */
  MX_GPIO_Init();
  MX_DMA_Init();
  MX_USART3_UART_Init();
  MX_TIM3_Init();
  MX_TIM14_Init();
  MX_UART4_Init();
  MX_TIM2_Init();
  MX_TIM8_Init();
  MX_TIM6_Init();
  MX_TIM13_Init();
  MX_ADC3_Init();
  MX_TIM12_Init();
  MX_TIM11_Init();
  MX_TIM4_Init();
  MX_TIM7_Init();
  MX_TIM5_Init();
  MX_I2C2_Init();
  MX_TIM9_Init();
  MX_TIM10_Init();

  /* Initialize interrupts */
  MX_NVIC_Init();
  /* USER CODE BEGIN 2 */
	linear_init = 1;
	if (linear_init == 1) {
		HAL_GPIO_WritePin(GPIOF, GPIO_PIN_4, 1); //정지
	}
	TIM3->CCR4 = 0;
	MPU6050_Init();

//	HAL_UART_Receive_IT(&huart3, &rxByte, 1);
	HAL_UART_Receive_IT(&huart3, &key_value, 1);
	//HAL_UART_Receive_IT(&huart4, &data, 1);
	HAL_UART_Receive_IT(&huart4, (uint8_t*) Rx_buffer, 1);

//	HAL_UART_Receive_IT(&huart4, &RxRX, 1);

	HAL_ADC_Start_DMA(&hadc3, (uint32_t*) ADC3_value, 3);

	HAL_TIM_Base_Start_IT(&htim6);  //pid
	HAL_TIM_Base_Start_IT(&htim7);  //센서
	HAL_TIM_Base_Start_IT(&htim14);  //RPM
	HAL_TIM_Base_Start_IT(&htim5);  //vt

	HAL_TIM_Base_Start_IT(&htim9);
	HAL_TIM_Base_Start_IT(&htim10);

	HAL_TIM_Encoder_Start(&htim2, TIM_CHANNEL_ALL);
	HAL_TIM_Encoder_Start(&htim4, TIM_CHANNEL_ALL);

	HAL_TIM_Base_Start_IT(&htim4);

	HAL_TIM_Base_Start_IT(&htim12);  //초음파 센서  안씀 >
	HAL_TIM_Base_Start_IT(&htim8);  //ADC 타이머

	HAL_TIM_PWM_Start(&htim3, TIM_CHANNEL_1);
	HAL_TIM_PWM_Start(&htim3, TIM_CHANNEL_2);
	HAL_TIM_PWM_Start(&htim3, TIM_CHANNEL_4);
	setvbuf(stdin, NULL, _IONBF, 0);

	gridInit(IsEmpty);
	setDpp(0, 0, 5, 5); //0,0 에서 1,2로
	readPath(lpp(), path);

	TIM3->CCR4 = 0;
	HAL_GPIO_WritePin(GPIOF, GPIO_PIN_4, 1); //정지
	HAL_GPIO_WritePin(GPIOC, GPIO_PIN_2, 1); //리니어  후진

	down_high_test = 0;
	ball_min_test = 0;
	x_go = 0;
	x_back = 0;
	y_go = 0;
	y_back = 0;
	ball_high = 0;

	RPM_X_go = 0;
	RPM_X_back = 0;
	RPM_Y_go = 0;
	RPM_Y_back = 0;

	PID_X_finish = 0;
	PID_Y_finish = 0;
//	downpart_run=0;
	ballscrew_up_run = 0;
	ballscrew_down_run = 0;
	pickup_run = 0;
	dropoff_run = 0;

	step_count_for_flag__ = 0;

	shaft_accel_flag = 0; //0:등속 ,1 가속

	DC_Y_go_sensor_flag = 0;
	DC_Y_back_sensor_flag = 0;

	//   DC_X_now_posiotion=0;
	DC_Y_now_posiotion = 0;

	HAL_GPIO_WritePin(GPIOG, GPIO_PIN_0, 1);

	HAL_GPIO_WritePin(GPIOB, GPIO_PIN_11, 1);

  /* USER CODE END 2 */

  /* Infinite loop */
	while (1) {

    /* USER CODE BEGIN 3 */

		if (tim12_flag == TRUE)  //0.1s
		{
			///////////////// 다운 버튼 깔짝
			if(  key_value=='>' || RxRX =='R')
			{		if (down_max_flag == 1 ) {

					tim9_flag = 0;
					down_max_flag_ = TRUE;
					down_max_flag = 0 ;
				}
				else if (down_max_flag_ == TRUE) {
					if (tim9_flag >= 2)   //0.1초 마다++ >> 10: 1s
					{
						down_part_DOWN(130, shaft_pulse_cycle);
						down_max_flag_ = FALSE;
					}

				}
			}
////////////////////////////////  어날리저

			 if (Analyzer.mov == TRUE)
			 {
				 tim9_flag = 0;
				 Analyzer.mov_ = TRUE;

				 Analyzer.mov = FALSE;
			 }
			 else if (Analyzer.mov_ == TRUE)
			 {

				 if (tim9_flag >= 14)   //0.1초 마다++ >> 2.5초 대기
				 {

					 if (rol % 2 == 0)  //짝수: x방향  후진
					 {

						 if (num == '1')
						 {
							 v_t_graph_DIR_BACK_X(targetS_X_BACK);
							 algo_x_back++;
						 }
						 else if (num == '2')
						 {
							 v_t_graph_DIR_BACK_X(targetS_X_BACK2);
							 algo_x_back2++;
						 }
					 }
				 else if (rol % 2 == 1)  //홀수 y방향  후진
				 {
					 if (num == '1')
					 {
							HAL_TIM_Encoder_Stop(&htim2, TIM_CHANNEL_ALL);
							HAL_TIM_Encoder_Start(&htim4, TIM_CHANNEL_ALL);

							HAL_TIM_PWM_Stop(&htim3, TIM_CHANNEL_1);
							HAL_TIM_PWM_Start(&htim3, TIM_CHANNEL_2);
							HAL_Delay(80);
						 v_t_graph_DIR_BACK_Y(targetS_Y_BACK);
						// v_t_graph_DIR_BACK_Y(targetS_Y_BACK);
						 algo_y_back++;
					 }

				 }
					 Analyzer.mov_ = FALSE;
				 }
			 }

			 else if (Analyzer.pov == TRUE)
			 {
				 tim9_flag = 0;
				 Analyzer.pov_ = TRUE;

				 Analyzer.pov = FALSE;
			 }
			 else if (Analyzer.pov_ == TRUE)
			 {
				 if (tim9_flag >= 14)   //0.1초 마다++ >> 2.5초 대기
				 {

					 if (rol % 2 == 0)  //짝수: x방향 전진
					 {
						 if (num == '1')
						 {
							 v_t_graph_DIR_GO_X(targetS_X_GO);  // x 앞으로
							 algo_x_go++;
						 }
						 else if (num == '2')
						 {
							 v_t_graph_DIR_GO_X(targetS_X_GO2);  // x 앞으로
							 algo_x_go2++;
						 }
					 }
					 else if (rol % 2 == 1)  //홀수 y방향  전진
					 {
						 if (num == '1')
						 {
								HAL_TIM_Encoder_Stop(&htim2, TIM_CHANNEL_ALL);
								HAL_TIM_Encoder_Start(&htim4, TIM_CHANNEL_ALL);

								HAL_TIM_PWM_Stop(&htim3, TIM_CHANNEL_1);
								HAL_TIM_PWM_Start(&htim3, TIM_CHANNEL_2);
							//	HAL_Delay(80);
							 v_t_graph_DIR_GO_Y(targetS_Y_GO);
							// v_t_graph_DIR_GO_Y(targetS_Y_GO);
							 algo_y_go++;

						 }

					 }
						 Analyzer.pov_ = FALSE;
				 }
			 }

			 else if (Analyzer.rol == TRUE)
			 {
				 tim9_flag = 0;
				 Analyzer.rol_ = TRUE;

				 Analyzer.rol = FALSE;
			 }
			 else if (Analyzer.rol_ == TRUE)
			 {
				 if (tim9_flag >= 14)   //0.1초 마다++ >> 2.5초 대기
				 {

					 if (num == '0')
					 {
						 z_axis_DOWN(400 * 6 * 2 + 700, ball_screw_pulse_cycle); //볼 내림 x -> y
						 algo_rol_down++;
					 }
					 else if (num == '1')
					 {
						 z_axis_UP(400 * 6 * 2, ball_screw_pulse_cycle); //볼 올림 y -> x
						 algo_rol_up++;
					 }
					 rol++;

				 	 Analyzer.rol_ = FALSE;
				 }
			 }

			 else if (Analyzer.pik == TRUE)
			 {
				 tim9_flag = 0;
				 Analyzer.pik_ = TRUE;

				 Analyzer.pik = FALSE;
			 }
			 else if (Analyzer.pik_ == TRUE)
			 {
				 if (tim9_flag >= 15)   //0.1초 마다++ >> 2.5초 대기
				 {

					 pik++;  //픽이 홀수다 : 물건을 들고있는 상태임, 짝수: 빈 상태
					 //			HAL_Delay(2500);
					 if (num == '1')
					 {
						 FALSE_Init();

						 Manual_mode.box_pickup = TRUE;
						 box_floor_test_pick = 1;
						 algo_pik1++;
					 }
					 else if (num == '2')
					 {
						 FALSE_Init();

						 Manual_mode.box_pickup = TRUE;
						 box_floor_test_pick = 2;
						 algo_pik2++;
					 }
					 else if (num == '3')
					 {
						 FALSE_Init();

						 Manual_mode.box_pickup = TRUE;
						 box_floor_test_pick = 3;
						 algo_pik3++;
					 }

					Analyzer.pik_ = FALSE;
				 }
			 }

			 else if (Analyzer.plc == TRUE)
			 {
				 tim9_flag = 0;
				 Analyzer.plc_ = TRUE;

				 Analyzer.plc = FALSE;
			 }
			 else if (Analyzer.plc_ == TRUE)
			 {
				 if (tim9_flag >= 9)   //0.1초 마다++ >> 2.5초 대
				 {

					 plc++;
					 //		HAL_Delay(2500);
					 if (num == '1')
					 {
						 FALSE_Init();

						 Manual_mode.Box_dropoff = TRUE;
						 box_floor_test_drop = 1;
						 algo_plc1++;
					 }
					 else if (num == '2')
					 {
						 FALSE_Init();

						 Manual_mode.Box_dropoff = TRUE;
						 box_floor_test_drop = 2;
						 algo_plc2++;
					 }
					 else if (num == '3')
					 {
						 FALSE_Init();

						 Manual_mode.Box_dropoff = TRUE;
						 box_floor_test_drop = 3;
						 algo_plc3++;
					 }
					Analyzer.plc_ = FALSE;
				}
			 }

			 //	asda++; // ok

			 //if(asda==100) HAL_Delay(1000-1);

		///////////	//어날리저 수정

/*
			if (Analyzer.mov == TRUE)
			{

				if (rol % 2 == 0)  //짝수: x방향  후진
				{
					if (num == '1')
					{
						v_t_graph_DIR_BACK_X(targetS_X_BACK);  // x 후진
					}
					else if (num == '2')
					{
						v_t_graph_DIR_BACK_X(targetS_X_BACK2);  // x 후진2
					}
				}
				else if (rol % 2 == 1)  //홀수 y방향  후진
				{
					if (num == '1')
					{
						v_t_graph_DIR_BACK_Y(targetS_Y_BACK);
					}

				}
				HAL_Delay(700-1);
					Analyzer.mov = FALSE;
			}
			else if (Analyzer.pov == TRUE)
			{

				if (rol % 2 == 0)  //짝수: x방향 전진
				{
					if (num == '1')
					{
						v_t_graph_DIR_GO_X(targetS_X_GO);  // x 앞으로
					}
					else if (num == '2')
					{
						v_t_graph_DIR_GO_X(targetS_X_GO2);  // x 앞으로
					}
				}
				else if (rol % 2 == 1)  //홀수 y방향  전진
				{
					if (num == '1')
					{
						v_t_graph_DIR_GO_Y(targetS_Y_GO);
					}

				}
				HAL_Delay(700-1);
				Analyzer.pov = FALSE;
		}
		else if (Analyzer.rol == TRUE)
		{

				if (num == '0')
				{
					z_axis_DOWN(400 * 6 * 2 + 700, ball_screw_pulse_cycle); //볼 내림 x -> y

				}
				else if (num == '1')
				{
					z_axis_UP(400 * 6 * 2, ball_screw_pulse_cycle); //볼 올림 y -> x

				}
				rol++;
				HAL_Delay(700-1);

							Analyzer.rol = FALSE;
		}
		else if (Analyzer.pik == TRUE)
		{
				pik++;  //픽이 홀수다 : 물건을 들고있는 상태임, 짝수: 빈 상태
				//			HAL_Delay(2500);
				if (num == '1')
				{
					FALSE_Init();

					Manual_mode.box_pickup = TRUE;
					box_floor_test_pick = 1;
				}
				else if (num == '2')
				{
					FALSE_Init();

					Manual_mode.box_pickup = TRUE;
					box_floor_test_pick = 2;
				}
				else if (num == '3')
				{
					FALSE_Init();

					Manual_mode.box_pickup = TRUE;
					box_floor_test_pick = 3;
				}

				HAL_Delay(4000-1);
							Analyzer.pik = FALSE;
		}
		else if (Analyzer.plc == TRUE)
		{

				plc++;
				//		HAL_Delay(2500);
				if (num == '1')
				{
					FALSE_Init();

					Manual_mode.Box_dropoff = TRUE;
					box_floor_test_drop = 1;
				}
				else if (num == '2')
				{
					FALSE_Init();

					Manual_mode.Box_dropoff = TRUE;
					box_floor_test_drop = 2;
				}
				else if (num == '3')
				{
					FALSE_Init();

					Manual_mode.Box_dropoff = TRUE;
					box_floor_test_drop = 3;
				}
				HAL_Delay(700-1);

					Analyzer.plc = FALSE;
	}
*/

//////////////////////////
			tim12_flag = FALSE;

		}

		/*
		 if (DC_Y_go_sensor_flag == 1 && DC_Y_now_posiotion == 1) {
		 i_v_t_count = 0;
		 HAL_Delay(1500);
		 Finish_flag.y_go = TRUE; // 전진
		 paser_flag = 1;

		 y_go++;
		 DC_Y_go_sensor_flag = 0;
		 } else if (DC_Y_back_sensor_flag == 1 && DC_Y_now_posiotion == 0) {
		 i_v_t_count = 0;
		 HAL_Delay(1500);
		 Finish_flag.y_back = TRUE; // 후진
		 paser_flag = 1;

		 y_back++;

		 DC_Y_back_sensor_flag = 0;
		 }
		 */
		////////////////////

		if (tim6_flag == 1)  //1ms
				{
			//		distance_sensor();  //거리 센서
			//		MPU6050_Read_Accel();  //MPU떄문에 거리센서 평균이 계산이 느려짐
			//		MPU6050_Read_Gyro();

			tim6_flag = 0;
		}
		if (key_value == '#')
			Manual_Mode_Y1(1, 2, box_floor_test_pick, box_floor_test_drop);

		if (key_value == '!')
			Manual_Mode_X1(2, 1, box_floor_test_pick, box_floor_test_drop);

		if (key_value == '@')
			Manual_Mode_X2(3, 1, box_floor_test_pick, box_floor_test_drop);

		if (key_value == '$')
			Manual_Mode_X1Y1(2, 2, box_floor_test_pick, box_floor_test_drop);

		if (key_value == '%')

			Manual_Mode_X2Y1(3, 2, box_floor_test_pick, box_floor_test_drop);

		if ((Manual_mode.box_pickup == TRUE) && (RPM_X == 0) && (RPM_Y == 0)) {
		i_v_t_count = 0;

					Box_pickup(box_floor_test_pick);
				}

				if ((Manual_mode.Box_dropoff == TRUE) && (RPM_X == 0) && (RPM_Y == 0)) {
					i_v_t_count = 0;
					Box_dropoff(box_floor_test_drop);

				}

//		if (down_max_flag == 1) {
//			HAL_Delay(140);
//			down_part_DOWN(130, shaft_pulse_cycle);
//			down_max_flag = 0;
//		}
		/*  //이거 대신 아래꺼 사용
		 if(PID_Y_finish==1)
		 {
		 HAL_Delay(800);
		 RPM_Y_go=0;
		 RPM_Y_back=0;

		 save_Y_IN=0;
		 PID_Y_finish=0;
		 }

		 if(PID_X_finish==1)
		 {
		 HAL_Delay(400);
		 RPM_X_go=0;
		 RPM_X_back=0;

		 PID_X_finish=0;
		 }
		 */
		if (photo_X_go == TRUE) {
			if (RPM_X == 0) {
				HAL_Delay(200);
				RPM_X_go = 0;
				RPM_X_back = 0;

				save_X_IN = 0;
				//	PID_X_finish=0;
				photo_X_go = FALSE;
			}

		} else if (photo_X_back == TRUE) {
			if (RPM_X == 0) {
				HAL_Delay(200);
				RPM_X_go = 0;
				RPM_X_back = 0;

				save_X_IN = 0;
				//	PID_X_finish=0;
				photo_X_back = FALSE;

			}
		}
		/*		if(photo_Y_go == TRUE)
		 {
		 if(RPM_Y ==0)
		 {
		 HAL_Delay(400);
		 RPM_Y_go=0;
		 RPM_Y_back=0;

		 save_Y_IN=0;
		 //	PID_Y_finish=0;
		 photo_Y_go=FALSE;
		 }
		 }
		 else if(photo_Y_back == TRUE)
		 {
		 if(RPM_Y ==0)
		 {
		 HAL_Delay(400);
		 RPM_Y_go=0;
		 RPM_Y_back=0;

		 save_Y_IN=0;
		 //	PID_Y_finish=0;
		 photo_Y_back=FALSE;
		 }
		 }
		 */

		//알고리즘 통신
		if (Transfer_finish) {

			fillQueue(Rx_data);
			//	int i = 0;
			pased_flag = '0';
			//		for (i = 0; i < countCmd(Rx_data); i++) {
			//			paser(Rx_data);
			//			//count____++;
			//		}
			paser(Rx_data);

			Transfer_finish = 0;
		}

		if (tim5_flag == 1) { //0.01s
			if (paser_flag == 1) {
				paser(Rx_data);
				//		HAL_Delay(1500);

				paser_flag = 0;
				count____++;
			}
			tim5_flag = 0;
		}

	}
  /* USER CODE END 3 */
}

void SystemClock_Config(void)
{
  RCC_OscInitTypeDef RCC_OscInitStruct = {0};
  RCC_ClkInitTypeDef RCC_ClkInitStruct = {0};

  /** Configure the main internal regulator output voltage
  */
  __HAL_RCC_PWR_CLK_ENABLE();
  __HAL_PWR_VOLTAGESCALING_CONFIG(PWR_REGULATOR_VOLTAGE_SCALE1);

  /** Initializes the RCC Oscillators according to the specified parameters
  * in the RCC_OscInitTypeDef structure.
  */
  RCC_OscInitStruct.OscillatorType = RCC_OSCILLATORTYPE_HSE;
  RCC_OscInitStruct.HSEState = RCC_HSE_BYPASS;
  RCC_OscInitStruct.PLL.PLLState = RCC_PLL_ON;
  RCC_OscInitStruct.PLL.PLLSource = RCC_PLLSOURCE_HSE;
  RCC_OscInitStruct.PLL.PLLM = 4;
  RCC_OscInitStruct.PLL.PLLN = 168;
  RCC_OscInitStruct.PLL.PLLP = RCC_PLLP_DIV2;
  RCC_OscInitStruct.PLL.PLLQ = 7;
  if (HAL_RCC_OscConfig(&RCC_OscInitStruct) != HAL_OK)
  {
    Error_Handler();
  }

  /** Initializes the CPU, AHB and APB buses clocks
  */
  RCC_ClkInitStruct.ClockType = RCC_CLOCKTYPE_HCLK|RCC_CLOCKTYPE_SYSCLK
                              |RCC_CLOCKTYPE_PCLK1|RCC_CLOCKTYPE_PCLK2;
  RCC_ClkInitStruct.SYSCLKSource = RCC_SYSCLKSOURCE_PLLCLK;
  RCC_ClkInitStruct.AHBCLKDivider = RCC_SYSCLK_DIV1;
  RCC_ClkInitStruct.APB1CLKDivider = RCC_HCLK_DIV4;
  RCC_ClkInitStruct.APB2CLKDivider = RCC_HCLK_DIV2;

  if (HAL_RCC_ClockConfig(&RCC_ClkInitStruct, FLASH_LATENCY_5) != HAL_OK)
  {
    Error_Handler();
  }
}

/**
  * @brief NVIC Configuration.
  * @retval None
  */
static void MX_NVIC_Init(void)
{
  /* EXTI3_IRQn interrupt configuration */
  HAL_NVIC_SetPriority(EXTI3_IRQn, 0, 0);
  HAL_NVIC_EnableIRQ(EXTI3_IRQn);
}

static void MX_ADC3_Init(void)
{

  ADC_ChannelConfTypeDef sConfig = {0};

  /** Configure the global features of the ADC (Clock, Resolution, Data Alignment and number of conversion)
  */
  hadc3.Instance = ADC3;
  hadc3.Init.ClockPrescaler = ADC_CLOCK_SYNC_PCLK_DIV4;
  hadc3.Init.Resolution = ADC_RESOLUTION_12B;
  hadc3.Init.ScanConvMode = ENABLE;
  hadc3.Init.ContinuousConvMode = DISABLE;
  hadc3.Init.DiscontinuousConvMode = ENABLE;
  hadc3.Init.NbrOfDiscConversion = 3;
  hadc3.Init.ExternalTrigConvEdge = ADC_EXTERNALTRIGCONVEDGE_RISING;
  hadc3.Init.ExternalTrigConv = ADC_EXTERNALTRIGCONV_T8_TRGO;
  hadc3.Init.DataAlign = ADC_DATAALIGN_RIGHT;
  hadc3.Init.NbrOfConversion = 3;
  hadc3.Init.DMAContinuousRequests = ENABLE;
  hadc3.Init.EOCSelection = ADC_EOC_SINGLE_CONV;
  if (HAL_ADC_Init(&hadc3) != HAL_OK)
  {
    Error_Handler();
  }

  /** Configure for the selected ADC regular channel its corresponding rank in the sequencer and its sample time.
  */
  sConfig.Channel = ADC_CHANNEL_13;
  sConfig.Rank = 1;
  sConfig.SamplingTime = ADC_SAMPLETIME_480CYCLES;
  if (HAL_ADC_ConfigChannel(&hadc3, &sConfig) != HAL_OK)
  {
    Error_Handler();
  }

  /** Configure for the selected ADC regular channel its corresponding rank in the sequencer and its sample time.
  */
  sConfig.Channel = ADC_CHANNEL_10;
  sConfig.Rank = 2;
  if (HAL_ADC_ConfigChannel(&hadc3, &sConfig) != HAL_OK)
  {
    Error_Handler();
  }

  /** Configure for the selected ADC regular channel its corresponding rank in the sequencer and its sample time.
  */
  sConfig.Channel = ADC_CHANNEL_11;
  sConfig.Rank = 3;
  if (HAL_ADC_ConfigChannel(&hadc3, &sConfig) != HAL_OK)
  {
    Error_Handler();
  }

}

static void MX_I2C2_Init(void)
{

  hi2c2.Instance = I2C2;
  hi2c2.Init.ClockSpeed = 100000;
  hi2c2.Init.DutyCycle = I2C_DUTYCYCLE_2;
  hi2c2.Init.OwnAddress1 = 0;
  hi2c2.Init.AddressingMode = I2C_ADDRESSINGMODE_7BIT;
  hi2c2.Init.DualAddressMode = I2C_DUALADDRESS_DISABLE;
  hi2c2.Init.OwnAddress2 = 0;
  hi2c2.Init.GeneralCallMode = I2C_GENERALCALL_DISABLE;
  hi2c2.Init.NoStretchMode = I2C_NOSTRETCH_DISABLE;
  if (HAL_I2C_Init(&hi2c2) != HAL_OK)
  {
    Error_Handler();
  }

  /** Configure Analogue filter
  */
  if (HAL_I2CEx_ConfigAnalogFilter(&hi2c2, I2C_ANALOGFILTER_ENABLE) != HAL_OK)
  {
    Error_Handler();
  }

  /** Configure Digital filter
  */
  if (HAL_I2CEx_ConfigDigitalFilter(&hi2c2, 0) != HAL_OK)
  {
    Error_Handler();
  }

}

static void MX_TIM2_Init(void)
{

  TIM_Encoder_InitTypeDef sConfig = {0};
  TIM_MasterConfigTypeDef sMasterConfig = {0};

  htim2.Instance = TIM2;
  htim2.Init.Prescaler = 5-1;
  htim2.Init.CounterMode = TIM_COUNTERMODE_UP;
  htim2.Init.Period = 0xffffffff;
  htim2.Init.ClockDivision = TIM_CLOCKDIVISION_DIV1;
  htim2.Init.AutoReloadPreload = TIM_AUTORELOAD_PRELOAD_DISABLE;
  sConfig.EncoderMode = TIM_ENCODERMODE_TI12;
  sConfig.IC1Polarity = TIM_ICPOLARITY_RISING;
  sConfig.IC1Selection = TIM_ICSELECTION_DIRECTTI;
  sConfig.IC1Prescaler = TIM_ICPSC_DIV1;
  sConfig.IC1Filter = 0;
  sConfig.IC2Polarity = TIM_ICPOLARITY_RISING;
  sConfig.IC2Selection = TIM_ICSELECTION_DIRECTTI;
  sConfig.IC2Prescaler = TIM_ICPSC_DIV1;
  sConfig.IC2Filter = 0;
  if (HAL_TIM_Encoder_Init(&htim2, &sConfig) != HAL_OK)
  {
    Error_Handler();
  }
  sMasterConfig.MasterOutputTrigger = TIM_TRGO_RESET;
  sMasterConfig.MasterSlaveMode = TIM_MASTERSLAVEMODE_DISABLE;
  if (HAL_TIMEx_MasterConfigSynchronization(&htim2, &sMasterConfig) != HAL_OK)
  {
    Error_Handler();
  }

}

static void MX_TIM3_Init(void)
{

  TIM_ClockConfigTypeDef sClockSourceConfig = {0};
  TIM_MasterConfigTypeDef sMasterConfig = {0};
  TIM_OC_InitTypeDef sConfigOC = {0};

  htim3.Instance = TIM3;
  htim3.Init.Prescaler = 84-1;
  htim3.Init.CounterMode = TIM_COUNTERMODE_UP;
  htim3.Init.Period = 10000-1;
  htim3.Init.ClockDivision = TIM_CLOCKDIVISION_DIV1;
  htim3.Init.AutoReloadPreload = TIM_AUTORELOAD_PRELOAD_DISABLE;
  if (HAL_TIM_Base_Init(&htim3) != HAL_OK)
  {
    Error_Handler();
  }
  sClockSourceConfig.ClockSource = TIM_CLOCKSOURCE_INTERNAL;
  if (HAL_TIM_ConfigClockSource(&htim3, &sClockSourceConfig) != HAL_OK)
  {
    Error_Handler();
  }
  if (HAL_TIM_PWM_Init(&htim3) != HAL_OK)
  {
    Error_Handler();
  }
  sMasterConfig.MasterOutputTrigger = TIM_TRGO_RESET;
  sMasterConfig.MasterSlaveMode = TIM_MASTERSLAVEMODE_DISABLE;
  if (HAL_TIMEx_MasterConfigSynchronization(&htim3, &sMasterConfig) != HAL_OK)
  {
    Error_Handler();
  }
  sConfigOC.OCMode = TIM_OCMODE_PWM1;
  sConfigOC.Pulse = 600;
  sConfigOC.OCPolarity = TIM_OCPOLARITY_HIGH;
  sConfigOC.OCFastMode = TIM_OCFAST_DISABLE;
  if (HAL_TIM_PWM_ConfigChannel(&htim3, &sConfigOC, TIM_CHANNEL_1) != HAL_OK)
  {
    Error_Handler();
  }
  if (HAL_TIM_PWM_ConfigChannel(&htim3, &sConfigOC, TIM_CHANNEL_2) != HAL_OK)
  {
    Error_Handler();
  }
  sConfigOC.Pulse = 0;
  if (HAL_TIM_PWM_ConfigChannel(&htim3, &sConfigOC, TIM_CHANNEL_4) != HAL_OK)
  {
    Error_Handler();
  }
  HAL_TIM_MspPostInit(&htim3);

}

static void MX_TIM4_Init(void)
{

  TIM_Encoder_InitTypeDef sConfig = {0};
  TIM_MasterConfigTypeDef sMasterConfig = {0};

  htim4.Instance = TIM4;
  htim4.Init.Prescaler = 16-1;
  htim4.Init.CounterMode = TIM_COUNTERMODE_UP;
  htim4.Init.Period = 0xFFFF-1;
  htim4.Init.ClockDivision = TIM_CLOCKDIVISION_DIV1;
  htim4.Init.AutoReloadPreload = TIM_AUTORELOAD_PRELOAD_DISABLE;
  sConfig.EncoderMode = TIM_ENCODERMODE_TI12;
  sConfig.IC1Polarity = TIM_ICPOLARITY_RISING;
  sConfig.IC1Selection = TIM_ICSELECTION_DIRECTTI;
  sConfig.IC1Prescaler = TIM_ICPSC_DIV1;
  sConfig.IC1Filter = 0;
  sConfig.IC2Polarity = TIM_ICPOLARITY_RISING;
  sConfig.IC2Selection = TIM_ICSELECTION_DIRECTTI;
  sConfig.IC2Prescaler = TIM_ICPSC_DIV1;
  sConfig.IC2Filter = 0;
  if (HAL_TIM_Encoder_Init(&htim4, &sConfig) != HAL_OK)
  {
    Error_Handler();
  }
  sMasterConfig.MasterOutputTrigger = TIM_TRGO_RESET;
  sMasterConfig.MasterSlaveMode = TIM_MASTERSLAVEMODE_DISABLE;
  if (HAL_TIMEx_MasterConfigSynchronization(&htim4, &sMasterConfig) != HAL_OK)
  {
    Error_Handler();
  }

}

static void MX_TIM5_Init(void)
{

  TIM_ClockConfigTypeDef sClockSourceConfig = {0};
  TIM_MasterConfigTypeDef sMasterConfig = {0};

  htim5.Instance = TIM5;
  htim5.Init.Prescaler = 84-1;
  htim5.Init.CounterMode = TIM_COUNTERMODE_UP;
  htim5.Init.Period = 10000-1;
  htim5.Init.ClockDivision = TIM_CLOCKDIVISION_DIV1;
  htim5.Init.AutoReloadPreload = TIM_AUTORELOAD_PRELOAD_DISABLE;
  if (HAL_TIM_Base_Init(&htim5) != HAL_OK)
  {
    Error_Handler();
  }
  sClockSourceConfig.ClockSource = TIM_CLOCKSOURCE_INTERNAL;
  if (HAL_TIM_ConfigClockSource(&htim5, &sClockSourceConfig) != HAL_OK)
  {
    Error_Handler();
  }
  sMasterConfig.MasterOutputTrigger = TIM_TRGO_RESET;
  sMasterConfig.MasterSlaveMode = TIM_MASTERSLAVEMODE_DISABLE;
  if (HAL_TIMEx_MasterConfigSynchronization(&htim5, &sMasterConfig) != HAL_OK)
  {
    Error_Handler();
  }

}

static void MX_TIM6_Init(void)
{

  /* USER CODE BEGIN TIM6_Init 0 */
	//0.001s = 1ms
	//PID 샘플링 주기
  /* USER CODE END TIM6_Init 0 */

  TIM_MasterConfigTypeDef sMasterConfig = {0};

  htim6.Instance = TIM6;
  htim6.Init.Prescaler = 84-1;
  htim6.Init.CounterMode = TIM_COUNTERMODE_UP;
  htim6.Init.Period = 1000-1;
  htim6.Init.AutoReloadPreload = TIM_AUTORELOAD_PRELOAD_DISABLE;
  if (HAL_TIM_Base_Init(&htim6) != HAL_OK)
  {
    Error_Handler();
  }
  sMasterConfig.MasterOutputTrigger = TIM_TRGO_RESET;
  sMasterConfig.MasterSlaveMode = TIM_MASTERSLAVEMODE_DISABLE;
  if (HAL_TIMEx_MasterConfigSynchronization(&htim6, &sMasterConfig) != HAL_OK)
  {
    Error_Handler();
  }

}

static void MX_TIM7_Init(void)
{

  TIM_MasterConfigTypeDef sMasterConfig = {0};

  htim7.Instance = TIM7;
  htim7.Init.Prescaler = 84-1;
  htim7.Init.CounterMode = TIM_COUNTERMODE_UP;
  htim7.Init.Period = 100-1;
  htim7.Init.AutoReloadPreload = TIM_AUTORELOAD_PRELOAD_DISABLE;
  if (HAL_TIM_Base_Init(&htim7) != HAL_OK)
  {
    Error_Handler();
  }
  sMasterConfig.MasterOutputTrigger = TIM_TRGO_RESET;
  sMasterConfig.MasterSlaveMode = TIM_MASTERSLAVEMODE_DISABLE;
  if (HAL_TIMEx_MasterConfigSynchronization(&htim7, &sMasterConfig) != HAL_OK)
  {
    Error_Handler();
  }

}

static void MX_TIM8_Init(void)
{

  /* USER CODE BEGIN TIM8_Init 0 */
	//ADC 측정 타이머 , 나중엔 필요 x
  /* USER CODE END TIM8_Init 0 */

  TIM_ClockConfigTypeDef sClockSourceConfig = {0};
  TIM_MasterConfigTypeDef sMasterConfig = {0};
  TIM_OC_InitTypeDef sConfigOC = {0};
  TIM_BreakDeadTimeConfigTypeDef sBreakDeadTimeConfig = {0};

  htim8.Instance = TIM8;
  htim8.Init.Prescaler = 84-1;
  htim8.Init.CounterMode = TIM_COUNTERMODE_UP;
  htim8.Init.Period = 300-1;
  htim8.Init.ClockDivision = TIM_CLOCKDIVISION_DIV1;
  htim8.Init.RepetitionCounter = 0;
  htim8.Init.AutoReloadPreload = TIM_AUTORELOAD_PRELOAD_DISABLE;
  if (HAL_TIM_Base_Init(&htim8) != HAL_OK)
  {
    Error_Handler();
  }
  sClockSourceConfig.ClockSource = TIM_CLOCKSOURCE_INTERNAL;
  if (HAL_TIM_ConfigClockSource(&htim8, &sClockSourceConfig) != HAL_OK)
  {
    Error_Handler();
  }
  if (HAL_TIM_OC_Init(&htim8) != HAL_OK)
  {
    Error_Handler();
  }
  sMasterConfig.MasterOutputTrigger = TIM_TRGO_UPDATE;
  sMasterConfig.MasterSlaveMode = TIM_MASTERSLAVEMODE_DISABLE;
  if (HAL_TIMEx_MasterConfigSynchronization(&htim8, &sMasterConfig) != HAL_OK)
  {
    Error_Handler();
  }
  sConfigOC.OCMode = TIM_OCMODE_TIMING;
  sConfigOC.Pulse = 2000;
  sConfigOC.OCPolarity = TIM_OCPOLARITY_HIGH;
  sConfigOC.OCFastMode = TIM_OCFAST_DISABLE;
  sConfigOC.OCIdleState = TIM_OCIDLESTATE_RESET;
  sConfigOC.OCNIdleState = TIM_OCNIDLESTATE_RESET;
  if (HAL_TIM_OC_ConfigChannel(&htim8, &sConfigOC, TIM_CHANNEL_4) != HAL_OK)
  {
    Error_Handler();
  }
  sBreakDeadTimeConfig.OffStateRunMode = TIM_OSSR_DISABLE;
  sBreakDeadTimeConfig.OffStateIDLEMode = TIM_OSSI_DISABLE;
  sBreakDeadTimeConfig.LockLevel = TIM_LOCKLEVEL_OFF;
  sBreakDeadTimeConfig.DeadTime = 0;
  sBreakDeadTimeConfig.BreakState = TIM_BREAK_DISABLE;
  sBreakDeadTimeConfig.BreakPolarity = TIM_BREAKPOLARITY_HIGH;
  sBreakDeadTimeConfig.AutomaticOutput = TIM_AUTOMATICOUTPUT_DISABLE;
  if (HAL_TIMEx_ConfigBreakDeadTime(&htim8, &sBreakDeadTimeConfig) != HAL_OK)
  {
    Error_Handler();
  }

}

static void MX_TIM9_Init(void)
{

  TIM_ClockConfigTypeDef sClockSourceConfig = {0};

  htim9.Instance = TIM9;
  htim9.Init.Prescaler = 16800-1;
  htim9.Init.CounterMode = TIM_COUNTERMODE_UP;
  htim9.Init.Period = 1000-1;
  htim9.Init.ClockDivision = TIM_CLOCKDIVISION_DIV1;
  htim9.Init.AutoReloadPreload = TIM_AUTORELOAD_PRELOAD_DISABLE;
  if (HAL_TIM_Base_Init(&htim9) != HAL_OK)
  {
    Error_Handler();
  }
  sClockSourceConfig.ClockSource = TIM_CLOCKSOURCE_INTERNAL;
  if (HAL_TIM_ConfigClockSource(&htim9, &sClockSourceConfig) != HAL_OK)
  {
    Error_Handler();
  }

}

static void MX_TIM10_Init(void)
{

  htim10.Instance = TIM10;
  htim10.Init.Prescaler = 16800-1;
  htim10.Init.CounterMode = TIM_COUNTERMODE_UP;
  htim10.Init.Period = 1000-1;
  htim10.Init.ClockDivision = TIM_CLOCKDIVISION_DIV1;
  htim10.Init.AutoReloadPreload = TIM_AUTORELOAD_PRELOAD_DISABLE;
  if (HAL_TIM_Base_Init(&htim10) != HAL_OK)
  {
    Error_Handler();
  }

}

static void MX_TIM11_Init(void)
{

  TIM_OC_InitTypeDef sConfigOC = {0};

  htim11.Instance = TIM11;
  htim11.Init.Prescaler = 168-1;
  htim11.Init.CounterMode = TIM_COUNTERMODE_UP;
  htim11.Init.Period = 800-1;
  htim11.Init.ClockDivision = TIM_CLOCKDIVISION_DIV1;
  htim11.Init.AutoReloadPreload = TIM_AUTORELOAD_PRELOAD_ENABLE;
  if (HAL_TIM_Base_Init(&htim11) != HAL_OK)
  {
    Error_Handler();
  }
  if (HAL_TIM_OC_Init(&htim11) != HAL_OK)
  {
    Error_Handler();
  }
  sConfigOC.OCMode = TIM_OCMODE_TOGGLE;
  sConfigOC.Pulse = 50;
  sConfigOC.OCPolarity = TIM_OCPOLARITY_HIGH;
  sConfigOC.OCFastMode = TIM_OCFAST_DISABLE;
  if (HAL_TIM_OC_ConfigChannel(&htim11, &sConfigOC, TIM_CHANNEL_1) != HAL_OK)
  {
    Error_Handler();
  }
  HAL_TIM_MspPostInit(&htim11);

}

static void MX_TIM12_Init(void)
{

  /* USER CODE BEGIN TIM12_Init 0 */
	// 초음파 센서
  /* USER CODE END TIM12_Init 0 */

  TIM_ClockConfigTypeDef sClockSourceConfig = {0};

  htim12.Instance = TIM12;
  htim12.Init.Prescaler = 8400-1;
  htim12.Init.CounterMode = TIM_COUNTERMODE_UP;
  htim12.Init.Period = 1000-1;
  htim12.Init.ClockDivision = TIM_CLOCKDIVISION_DIV1;
  htim12.Init.AutoReloadPreload = TIM_AUTORELOAD_PRELOAD_DISABLE;
  if (HAL_TIM_Base_Init(&htim12) != HAL_OK)
  {
    Error_Handler();
  }
  sClockSourceConfig.ClockSource = TIM_CLOCKSOURCE_INTERNAL;
  if (HAL_TIM_ConfigClockSource(&htim12, &sClockSourceConfig) != HAL_OK)
  {
    Error_Handler();
  }

}

static void MX_TIM13_Init(void)
{

  /* USER CODE BEGIN TIM13_Init 0 */
// 테스트 용
  /* USER CODE END TIM13_Init 0 */

  TIM_OC_InitTypeDef sConfigOC = {0};

  htim13.Instance = TIM13;
  htim13.Init.Prescaler = 84-1;
  htim13.Init.CounterMode = TIM_COUNTERMODE_UP;
  htim13.Init.Period = 800-1;
  htim13.Init.ClockDivision = TIM_CLOCKDIVISION_DIV1;
  htim13.Init.AutoReloadPreload = TIM_AUTORELOAD_PRELOAD_ENABLE;
  if (HAL_TIM_Base_Init(&htim13) != HAL_OK)
  {
    Error_Handler();
  }
  if (HAL_TIM_OC_Init(&htim13) != HAL_OK)
  {
    Error_Handler();
  }
  sConfigOC.OCMode = TIM_OCMODE_TOGGLE;
  sConfigOC.Pulse = 130;
  sConfigOC.OCPolarity = TIM_OCPOLARITY_HIGH;
  sConfigOC.OCFastMode = TIM_OCFAST_DISABLE;
  if (HAL_TIM_OC_ConfigChannel(&htim13, &sConfigOC, TIM_CHANNEL_1) != HAL_OK)
  {
    Error_Handler();
  }
  __HAL_TIM_ENABLE_OCxPRELOAD(&htim13, TIM_CHANNEL_1);
  /* USER CODE BEGIN TIM13_Init 2 */
	//HAL_TIM_MspPostInit(&htim13);
  /* USER CODE END TIM13_Init 2 */
  HAL_TIM_MspPostInit(&htim13);

}

static void MX_TIM14_Init(void)
{

  /* USER CODE BEGIN TIM14_Init 0 */
//RPM 측정
  /* USER CODE END TIM14_Init 0 */

  htim14.Instance = TIM14;
  htim14.Init.Prescaler = 84-1;
  htim14.Init.CounterMode = TIM_COUNTERMODE_UP;
  htim14.Init.Period = 10000-1;
  htim14.Init.ClockDivision = TIM_CLOCKDIVISION_DIV1;
  htim14.Init.AutoReloadPreload = TIM_AUTORELOAD_PRELOAD_DISABLE;
  if (HAL_TIM_Base_Init(&htim14) != HAL_OK)
  {
    Error_Handler();
  }
  /* USER CODE BEGIN TIM14_Init 2 */
//	TIM14->DIER |= (1 << 0);   // CC1IE: Enable the Tim14 UG interrupt
//	NVIC->ISER[1] |= (1 << (45 - 32)); // TIM14_CC
//	TIM14->CR1 |= (1 << 0);	// CEN: Counter TIM14 enable
  /* USER CODE END TIM14_Init 2 */

}

static void MX_UART4_Init(void)
{

  huart4.Instance = UART4;
  huart4.Init.BaudRate = 230400;
  huart4.Init.WordLength = UART_WORDLENGTH_8B;
  huart4.Init.StopBits = UART_STOPBITS_1;
  huart4.Init.Parity = UART_PARITY_EVEN;
  huart4.Init.Mode = UART_MODE_TX_RX;
  huart4.Init.HwFlowCtl = UART_HWCONTROL_NONE;
  huart4.Init.OverSampling = UART_OVERSAMPLING_16;
  if (HAL_UART_Init(&huart4) != HAL_OK)
  {
    Error_Handler();
  }

}

static void MX_USART3_UART_Init(void)
{

  huart3.Instance = USART3;
  huart3.Init.BaudRate = 115200;
  huart3.Init.WordLength = UART_WORDLENGTH_8B;
  huart3.Init.StopBits = UART_STOPBITS_1;
  huart3.Init.Parity = UART_PARITY_NONE;
  huart3.Init.Mode = UART_MODE_TX_RX;
  huart3.Init.HwFlowCtl = UART_HWCONTROL_NONE;
  huart3.Init.OverSampling = UART_OVERSAMPLING_16;
  if (HAL_UART_Init(&huart3) != HAL_OK)
  {
    Error_Handler();
  }

}

static void MX_DMA_Init(void)
{

  /* DMA controller clock enable */
  __HAL_RCC_DMA2_CLK_ENABLE();

  /* DMA interrupt init */
  /* DMA2_Stream1_IRQn interrupt configuration */
  HAL_NVIC_SetPriority(DMA2_Stream1_IRQn, 0, 0);
  HAL_NVIC_EnableIRQ(DMA2_Stream1_IRQn);

}

static void MX_GPIO_Init(void)
{
  GPIO_InitTypeDef GPIO_InitStruct = {0};

  /* GPIO Ports Clock Enable */
  __HAL_RCC_GPIOC_CLK_ENABLE();
  __HAL_RCC_GPIOF_CLK_ENABLE();
  __HAL_RCC_GPIOH_CLK_ENABLE();
  __HAL_RCC_GPIOA_CLK_ENABLE();
  __HAL_RCC_GPIOB_CLK_ENABLE();
  __HAL_RCC_GPIOG_CLK_ENABLE();
  __HAL_RCC_GPIOD_CLK_ENABLE();
  __HAL_RCC_GPIOE_CLK_ENABLE();

  /*Configure GPIO pin Output Level */
  HAL_GPIO_WritePin(GPIOF, linear_DIR_Pin|GPIO_PIN_13|GPIO_PIN_14|GPIO_PIN_15, GPIO_PIN_RESET);

  /*Configure GPIO pin Output Level */
  HAL_GPIO_WritePin(linear_goback_GPIO_Port, linear_goback_Pin, GPIO_PIN_RESET);

  /*Configure GPIO pin Output Level */
  HAL_GPIO_WritePin(GPIOB, LD1_Pin|DC_M_GO_Y_Pin|DC_M_DIR_Y_Pin|LD3_Pin
                          |LD2_Pin, GPIO_PIN_RESET);

  /*Configure GPIO pin Output Level */
  HAL_GPIO_WritePin(GPIOG, DC_M_GO_X_Pin|GPIO_PIN_2|GPIO_PIN_3, GPIO_PIN_RESET);

  /*Configure GPIO pin Output Level */
  HAL_GPIO_WritePin(GPIOD, GPIO_PIN_7, GPIO_PIN_RESET);

  /*Configure GPIO pin Output Level */
  HAL_GPIO_WritePin(DC_M_DIR_X_GPIO_Port, DC_M_DIR_X_Pin, GPIO_PIN_RESET);

  /*Configure GPIO pin : USER_Btn_Pin */
  GPIO_InitStruct.Pin = USER_Btn_Pin;
  GPIO_InitStruct.Mode = GPIO_MODE_IT_RISING;
  GPIO_InitStruct.Pull = GPIO_NOPULL;
  HAL_GPIO_Init(USER_Btn_GPIO_Port, &GPIO_InitStruct);

  /*Configure GPIO pin : PF2 */
  GPIO_InitStruct.Pin = GPIO_PIN_2;
  GPIO_InitStruct.Mode = GPIO_MODE_INPUT;
  GPIO_InitStruct.Pull = GPIO_NOPULL;
  HAL_GPIO_Init(GPIOF, &GPIO_InitStruct);

  /*Configure GPIO pins : linear_DIR_Pin PF13 PF14 PF15 */
  GPIO_InitStruct.Pin = linear_DIR_Pin|GPIO_PIN_13|GPIO_PIN_14|GPIO_PIN_15;
  GPIO_InitStruct.Mode = GPIO_MODE_OUTPUT_PP;
  GPIO_InitStruct.Pull = GPIO_NOPULL;
  GPIO_InitStruct.Speed = GPIO_SPEED_FREQ_LOW;
  HAL_GPIO_Init(GPIOF, &GPIO_InitStruct);

  /*Configure GPIO pin : linear_goback_Pin */
  GPIO_InitStruct.Pin = linear_goback_Pin;
  GPIO_InitStruct.Mode = GPIO_MODE_OUTPUT_PP;
  GPIO_InitStruct.Pull = GPIO_NOPULL;
  GPIO_InitStruct.Speed = GPIO_SPEED_FREQ_LOW;
  HAL_GPIO_Init(linear_goback_GPIO_Port, &GPIO_InitStruct);

  /*Configure GPIO pin : DOWN_LIMIT_SW_Pin */
  GPIO_InitStruct.Pin = DOWN_LIMIT_SW_Pin;
  GPIO_InitStruct.Mode = GPIO_MODE_IT_FALLING;
  GPIO_InitStruct.Pull = GPIO_NOPULL;
  HAL_GPIO_Init(DOWN_LIMIT_SW_GPIO_Port, &GPIO_InitStruct);

  /*Configure GPIO pin : PA7 */
  GPIO_InitStruct.Pin = GPIO_PIN_7;
  GPIO_InitStruct.Mode = GPIO_MODE_INPUT;
  GPIO_InitStruct.Pull = GPIO_NOPULL;
  HAL_GPIO_Init(GPIOA, &GPIO_InitStruct);

  /*Configure GPIO pins : LD1_Pin DC_M_GO_Y_Pin LD3_Pin LD2_Pin */
  GPIO_InitStruct.Pin = LD1_Pin|DC_M_GO_Y_Pin|LD3_Pin|LD2_Pin;
  GPIO_InitStruct.Mode = GPIO_MODE_OUTPUT_PP;
  GPIO_InitStruct.Pull = GPIO_NOPULL;
  GPIO_InitStruct.Speed = GPIO_SPEED_FREQ_LOW;
  HAL_GPIO_Init(GPIOB, &GPIO_InitStruct);

  /*Configure GPIO pins : DC_M_GO_X_Pin PG2 PG3 */
  GPIO_InitStruct.Pin = DC_M_GO_X_Pin|GPIO_PIN_2|GPIO_PIN_3;
  GPIO_InitStruct.Mode = GPIO_MODE_OUTPUT_PP;
  GPIO_InitStruct.Pull = GPIO_NOPULL;
  GPIO_InitStruct.Speed = GPIO_SPEED_FREQ_LOW;
  HAL_GPIO_Init(GPIOG, &GPIO_InitStruct);

  /*Configure GPIO pin : DC_M_DIR_Y_Pin */
  GPIO_InitStruct.Pin = DC_M_DIR_Y_Pin;
  GPIO_InitStruct.Mode = GPIO_MODE_OUTPUT_PP;
  GPIO_InitStruct.Pull = GPIO_NOPULL;
  GPIO_InitStruct.Speed = GPIO_SPEED_FREQ_VERY_HIGH;
  HAL_GPIO_Init(DC_M_DIR_Y_GPIO_Port, &GPIO_InitStruct);

  /*Configure GPIO pin : USB_OverCurrent_Pin */
  GPIO_InitStruct.Pin = USB_OverCurrent_Pin;
  GPIO_InitStruct.Mode = GPIO_MODE_INPUT;
  GPIO_InitStruct.Pull = GPIO_NOPULL;
  HAL_GPIO_Init(USB_OverCurrent_GPIO_Port, &GPIO_InitStruct);

  /*Configure GPIO pins : BALL_HIGH_Pin PD2 PD6 */
  GPIO_InitStruct.Pin = BALL_HIGH_Pin|GPIO_PIN_2|GPIO_PIN_6;
  GPIO_InitStruct.Mode = GPIO_MODE_INPUT;
  GPIO_InitStruct.Pull = GPIO_NOPULL;
  HAL_GPIO_Init(GPIOD, &GPIO_InitStruct);

  /*Configure GPIO pin : BALL_MID_Pin */
  GPIO_InitStruct.Pin = BALL_MID_Pin;
  GPIO_InitStruct.Mode = GPIO_MODE_IT_FALLING;
  GPIO_InitStruct.Pull = GPIO_NOPULL;
  HAL_GPIO_Init(BALL_MID_GPIO_Port, &GPIO_InitStruct);

  /*Configure GPIO pin : PD7 */
  GPIO_InitStruct.Pin = GPIO_PIN_7;
  GPIO_InitStruct.Mode = GPIO_MODE_OUTPUT_PP;
  GPIO_InitStruct.Pull = GPIO_NOPULL;
  GPIO_InitStruct.Speed = GPIO_SPEED_FREQ_LOW;
  HAL_GPIO_Init(GPIOD, &GPIO_InitStruct);

  /*Configure GPIO pins : sensor_X_Pin sensor_Y_Pin */
  GPIO_InitStruct.Pin = sensor_X_Pin|sensor_Y_Pin;
  GPIO_InitStruct.Mode = GPIO_MODE_INPUT;
  GPIO_InitStruct.Pull = GPIO_NOPULL;
  HAL_GPIO_Init(GPIOB, &GPIO_InitStruct);

  /*Configure GPIO pin : DC_M_DIR_X_Pin */
  GPIO_InitStruct.Pin = DC_M_DIR_X_Pin;
  GPIO_InitStruct.Mode = GPIO_MODE_OUTPUT_PP;
  GPIO_InitStruct.Pull = GPIO_NOPULL;
  GPIO_InitStruct.Speed = GPIO_SPEED_FREQ_VERY_HIGH;
  HAL_GPIO_Init(DC_M_DIR_X_GPIO_Port, &GPIO_InitStruct);

  /* EXTI interrupt init*/
  HAL_NVIC_SetPriority(EXTI1_IRQn, 2, 0);
  HAL_NVIC_EnableIRQ(EXTI1_IRQn);

  HAL_NVIC_SetPriority(EXTI15_10_IRQn, 0, 0);
  HAL_NVIC_EnableIRQ(EXTI15_10_IRQn);

}

/* USER CODE BEGIN 4 */

float input_encodor_X_GO = 34816 * 2;
float input_encodor_X_BACK = -34816 * 2;

float input_encodor_Y_GO = 10880 * 2;
float input_encodor_Y_BACK = -10880 * 2;

PUTCHAR_PROTOTYPE  //테라텀
{
	HAL_UART_Transmit(&huart3, (uint8_t*) &ch, 1, HAL_MAX_DELAY);
	return ch;
}

void SerialSendChar_PC(uint8_t Ch1) // 1문자 보내기 함수
{
	// USART_SR_TXE(1<<7)=0?, TX Buffer NOT Empty?
	// TX buffer Empty되지 않으면 계속 대기(송신 가능한 상태까지 대기)
	while ((USART3->SR & 1 << 7) == RESET)
		;
	USART3->DR = (Ch1 & 0x01FF);	// 전송 (최대 9bit 이므로 0x01FF과 masking)
}

void SerialSendChar_ESP(uint8_t Ch2) // 1문자 보내기 함수
{
	while ((UART4->SR & 1 << 7) == RESET)
		;
	UART4->DR = (Ch2 & 0x01FF);
}

extern uint16_t ADC3_value[3];

extern float battery_V;
uint16_t RPM_uint16;
uint16_t battery_uint16;

uint8_t buffer[50];

void STM32_to_ESP(void)                    // ESP로 데이터 보냄
{

#define test 1
#if test ==1
//	GPIOB->ODR ^= 1 << 7;
	RPM_uint16 = RPM_X * 10;
	battery_uint16 = battery_V * 100;

	SerialSendChar_ESP('?');

	//테스트

	if (ADC3_value[0] >= 1000 && ADC3_value[0] <= 4095) {

		sprintf((char*) buffer, "%d\n\r", ADC3_value[0]);
		//		HAL_UART_Transmit(&huart3, buffer, strlen((char*) buffer), 100);
		sprintf((char*) buffer, "%d\n\r", ADC3_value[0]);
		//		HAL_UART_Transmit(&huart3, buffer, strlen((char*) buffer), 100);
		sprintf((char*) buffer, "%d\n\r", ADC3_value[0]);
		//	HAL_UART_Transmit(&huart3, buffer, strlen((char*) buffer), 100);

		//배터리, 속도 전송
		sprintf((char*) buffer, "%d", ADC3_value[0]);
		HAL_UART_Transmit(&huart4, buffer, strlen((char*) buffer), 100);
		sprintf((char*) buffer, "%d", ADC3_value[0]);
		HAL_UART_Transmit(&huart4, buffer, strlen((char*) buffer), 100);
		sprintf((char*) buffer, "%d", ADC3_value[0]);
		HAL_UART_Transmit(&huart4, buffer, strlen((char*) buffer), 100);
	}

#elif test == 2
		 GPIOB->ODR ^= 1 << 7;
		 RPM_uint16 = RPM_X * 10;
		 battery_uint16 = battery_V * 100;

		 SerialSendChar_ESP('?');
		 sprintf((char*) buffer, "%d", battery_uint16);
		 HAL_UART_Transmit(&huart4, buffer, strlen((char*) buffer), 100);
		 sprintf((char*) buffer, "%d", RPM_uint16);
		 HAL_UART_Transmit(&huart4, buffer, strlen((char*) buffer), 100);
		 sprintf((char*) buffer, "%d", battery_uint16);
		 HAL_UART_Transmit(&huart4, buffer, strlen((char*) buffer), 100);
		 #endif

}

extern uint16_t shaft_pulse_cycle;
extern uint16_t ball_screw_pulse_cycle;

uint16_t ball_step = 100;
uint32_t downpart_step = 25;
extern uint32_t step_pulse_count_tim13;
extern uint16_t step_pulse_count_tim11;

extern real_T rtb_Clock;
extern int downpart_accel_step_max;

void UART3_RX_PC_to_STM32(void) // UART3: STM32 <-> PC
{
#define com_test 1

#if com_test==0
	static uint16_t rxIndex = 0;
	static int start_found = 0;  // 시작 문자 발견 여부

	if (Rx_buffer[0] == '<') {  // 시작 문자 발견
		start_found = 1;
		memset(Rx_data, 0, DATA_SIZE);  // Rx_data 버퍼 초기화
		rxIndex = 0;  // 카운터 초기화
	} else if (Rx_buffer[0] == '>' && start_found) {  // 끝 문자 발견
		Rx_buffer[rxIndex] = '\0';
		Transfer_finish = 1;  // 완전한 메시지 수신 완료
		start_found = 0;  // 메시지 종료

	} else if (start_found) {
		Rx_data[rxIndex++] = Rx_buffer[0];  // 시작 문자 이후 데이터 저장

	}

	//for(int i=rxIndex ; i<100 ; i++)  rxData[i] = 0;

	//	rxIndex = 0; // 인덱스 초기화

	HAL_UART_Receive_IT(&huart3, (uint8_t*) Rx_buffer, 1);  // 다음 문자 수신 대기

	// 다음 바이트 수신 준비
	//     HAL_UART_Receive_IT(&huart3, &rxByte, 1);

#elif com_test ==1

	HAL_UART_Receive_IT(&huart3, &key_value, 1);

	printf("%d,^^ %c \r\n", key_value, key_value);

	switch (key_value) {
	case 'q':
		HAL_GPIO_WritePin(GPIOE, GPIO_PIN_0, 0);  //방향 go

		GPIOB->ODR |= 1 << 0;  //LD1

		break;

	case 'w':

		HAL_GPIO_WritePin(GPIOE, GPIO_PIN_0, 1);  //방향 back
		GPIOB->ODR &= ~1 << 0;  //LD1

		break;

	case '1':
		HAL_GPIO_WritePin(GPIOG, GPIO_PIN_0, 1);  //stop

		break;

	case '2':
		HAL_GPIO_WritePin(GPIOG, GPIO_PIN_0, 0);  //start
		HAL_TIM_Encoder_Start(&htim2, TIM_CHANNEL_ALL);
		HAL_TIM_PWM_Start(&htim3, TIM_CHANNEL_1);
		break;

	case '3':
		TIM3->CCR1 = 400;

		break;

	case '4':
		TIM3->CCR1 = 1700;

		break;

	case '5':
		TIM3->CCR1 = 6000;

		break;

		/////////////////////////////////////////////////////////////////y축 이동

	case 'd':
		HAL_GPIO_WritePin(GPIOB, GPIO_PIN_10, 0);  //y축 방향 go

		GPIOB->ODR |= 1 << 0;  //LD1

		break;

	case 'f':

		HAL_GPIO_WritePin(GPIOB, GPIO_PIN_10, 1);  //y축 방향 back
		GPIOB->ODR &= ~1 << 0;  //LD1

		break;

	case 'a':
		HAL_GPIO_WritePin(GPIOB, GPIO_PIN_11, 1);  //stop

		break;

	case 's':
		HAL_TIM_PWM_Start(&htim3, TIM_CHANNEL_2);
		HAL_TIM_Encoder_Start(&htim4, TIM_CHANNEL_ALL);
		HAL_GPIO_WritePin(GPIOB, GPIO_PIN_11, 0);  //start

		break;

	case 'e':
		TIM3->CCR2 = 400;

		break;

	case 'r':
		TIM3->CCR2 = 1700;

		break;
	case 't':
		TIM3->CCR2 = 6000;

		break;
		///////////////////////////////////////////////////////////////// x축 바퀴 PID

	case 'i':

		dc_motor_pid_X(34816);

		break;

	case 'o':
		dc_motor_pid_X(-34816);

		break;

//	case 'p':
//		dc_motor_pid_X(input_encodor_X_GO);

		//	break;

//	case '[':
//		dc_motor_pid_X(input_encodor_X_BACK);

//		break;
		////////////////////////////////////////////////////////////////x축 vt
	case 'I':  //30cm

		v_t_graph_DIR_GO_X(30);  //앞으로 30cm

		break;
	case 'O':

		v_t_graph_DIR_BACK_X(30); //뒤로 30cm

		break;
	case 'P':

		v_t_graph_DIR_GO_X(targetS_X_GO);  //앞으로

		break;
	case '{':

		v_t_graph_DIR_BACK_X(targetS_X_BACK); //뒤로

		break;
	case '}':

		v_t_graph_DIR_GO_X(targetS_X_GO2);  //앞으로

		break;

	case '|':

		v_t_graph_DIR_BACK_X(targetS_X_BACK2); //뒤로

		break;

		///////////////////////////////////////////////////////// y축  바퀴  PID

	case '8':

		dc_motor_pid_Y(10880);
		break;

	case '9':
		dc_motor_pid_Y(-10880);
		break;

//	case '0':
//		dc_motor_pid_Y(input_encodor_Y_GO);
//		break;
//	case '-':
//		dc_motor_pid_Y(input_encodor_Y_BACK);
//		break;
//////////////////////////////////////////////////////////      Y  VT
	case '*':

		v_t_graph_DIR_GO_Y(30);   //Y축 vt 앞
		break;

	case '(':
		v_t_graph_DIR_BACK_Y(30);   //뒤
		break;

	case ')':
		v_t_graph_DIR_GO_Y(targetS_Y_GO);
		break;

	case '_':
		v_t_graph_DIR_BACK_Y(targetS_Y_BACK);
		break;

		//////////////////////////////////////////////////////z축 볼스크류 스텝모터,  0625수정: 동작시에만 enable
	case 'j':
		HAL_GPIO_WritePin(GPIOG, GPIO_PIN_2, 1);  //정지
		step_pulse_count_tim11 = 0;
		break;

	case 'k':
		HAL_GPIO_WritePin(GPIOG, GPIO_PIN_2, 0);  //출발

		break;

	case 'l':   //cw 미소 이동             시계방향  위쪽
		z_axis_UP(ball_step, ball_screw_pulse_cycle);

		break;
	case ';':    //ccw 미소 이동           반시계방향  아래쪽
		z_axis_DOWN(ball_step, ball_screw_pulse_cycle);

		break;

	case 'L':   //cw              시계방향  위쪽
		z_axis_UP(400 * 6, ball_screw_pulse_cycle);

		break;
	case ':':    //ccw            반시계방향  아래쪽

		z_axis_DOWN(400 * 6 + 300, ball_screw_pulse_cycle);

		break;

		/////////////////////////////////////////////////////////////////////다운파트 축 스텝모터
	case 'm':
		HAL_GPIO_WritePin(GPIOF, GPIO_PIN_13, 1);  //정지 디스에이블
		step_pulse_count_tim13 = 0;
		break;

	case ',':
		HAL_GPIO_WritePin(GPIOF, GPIO_PIN_13, 0);  //출발  이네이블

		break;

	case 'M':  //가속
		FALSE_Init();
		down_part_UP_accel(downpart_step);

		break;
	case '<': //가속
		FALSE_Init();
		down_part_DOWN_accel(downpart_step);

		break;
	case '.':
		FALSE_Init();
		down_part_UP(downpart_step, shaft_pulse_cycle);

		break;

	case '/':
		FALSE_Init();
		down_part_DOWN(downpart_step, shaft_pulse_cycle);

		break;
	case '>':
		FALSE_Init();
		down_part_UP(400, shaft_pulse_cycle);

		break;

	case '?':
		FALSE_Init();
		down_part_DOWN(400, shaft_pulse_cycle);

		break;
//////////////////////////////////////////////////////////////////////////////////리니어 모터
//	case 'z':
//
//		HAL_GPIO_WritePin(GPIOF, GPIO_PIN_4, 1); //정지
//
//		break;
//
//	case 'x':
//
//		HAL_GPIO_WritePin(GPIOF, GPIO_PIN_4, 0);  //출발
//
//		break;
//	case 'c':
//
//		HAL_GPIO_WritePin(GPIOC, GPIO_PIN_2, 1);   //방향 후진
//
//		break;
//
//	case 'v':
//
//		HAL_GPIO_WritePin(GPIOC, GPIO_PIN_2, 0);  //방향  전진
//
//		break;
//
//	case 'b': //방향  전진
//
//		TIM3->CCR4 = 1500;
//
//		break;
//	case 'n': //방향  전진
//
//		TIM3->CCR4 = 4200;
//
//		break;
//	case 'h': //방향  전진
//
//		TIM3->CCR4 = 8000;
//
//		break;

	case 'z': //방향 초 전진

		linear_motor_GO(go_time);

		break;
	case 'x': //방향 초 전진

		linear_motor_BACK(back_time);

		break;

		/////////////////////////////////////////////////////////수동 조작
	case '!':  // (2,1)
		FALSE_Init();
		Manual_mode.target_2_1 = TRUE;

		break;
	case '@': //  (3,1)
		FALSE_Init();
		Manual_mode.target_3_1 = TRUE;

		break;

	case '#':  //(1,2)
		FALSE_Init();
		Manual_mode.target_1_2 = TRUE;

		break;

	case '$': // (2,2)
		FALSE_Init();
		Manual_mode.target_2_2 = TRUE;
		break;
	case '%':
		FALSE_Init();
		Manual_mode.target_3_2 = TRUE;
		break;

	case 'A':
		FALSE_Init();
		Manual_mode.box_pickup = TRUE;
		break;

	case 'S':
		FALSE_Init();
		Manual_mode.Box_dropoff = TRUE;
		break;

	case 'c':
		HAL_TIM_OC_Start_IT(&htim13, TIM_CHANNEL_1);
		break;
	case 'v':
			HAL_TIM_OC_Stop_IT(&htim13, TIM_CHANNEL_1);
			break;
	}
#endif
}

extern uint8_t linear_go_flag;

void UART4_RX_ESP_to_STM32(void) // UART4: esp <-> stm32
{

	static uint16_t rxIndex = 0;
	static int start_found = 0;  // 시작 문자 발견 여부

	if (Rx_buffer[0] == '<') {  // 시작 문자 발견
		start_found = 1;
		memset(Rx_data, 0, DATA_SIZE);  // Rx_data 버퍼 초기화
		rxIndex = 0;  // 카운터 초기화
	} else if (Rx_buffer[0] == '>' && start_found) {  // 끝 문자 발견
		Rx_buffer[rxIndex] = '\0';
		Transfer_finish = 1;  // 완전한 메시지 수신 완료
		start_found = 0;  // 메시지 종료

	} else if (start_found) {
		Rx_data[rxIndex++] = Rx_buffer[0];  // 시작 문자 이후 데이터 저장

	}

	HAL_UART_Receive_IT(&huart4, (uint8_t*) Rx_buffer, 1);  // 다음 문자 수신 대기

	if (Rx_buffer[0] == '[') {  // 시작 문자 발견
				start_found = 1;
				memset(Rx_data, 0, DATA_SIZE);  // Rx_data 버퍼 초기화
				rxIndex = 0;  // 카운터 초기화
			} else if (Rx_buffer[0] == ']' && start_found) {  // 끝 문자 발견
				Rx_buffer[rxIndex] = '\0';
				//Transfer_finish = 1;  // 완전한 메시지 수신 완료
				start_found = 0;  // 메시지 종료

			} else if (start_found) {
				RxRX = Rx_buffer[0];  // 시작 문자 이후 데이터 저장

			}

	HAL_UART_Receive_IT(&huart4, (uint8_t*) &RxRX, 1);

//HAL_UART_Receive_IT(&huart3, &key_value, 1);
//	 rxData[rxIndex++] = rxByte;
//
//		        // 종료 문자 !로 설정를 받으면 문자열 송신
//		        if (rxByte == '!') {
//		            rxData[rxIndex] = '\0'; // 문자열 종료 문자 추가
//		         //   HAL_UART_Transmit(&huart3, (uint8_t*)rxData, rxIndex, HAL_MAX_DELAY);
//
//		            sprintf((char*) buffer, "%s\n\r", rxData);
//		           		 HAL_UART_Transmit(&huart4, buffer, strlen((char*) buffer), 100);
//
//
//
//		            for(int i=rxIndex ; i<100 ; i++)  rxData[i] = 0;
//
//		            	rxIndex = 0; // 인덱스 초기화
//		        }
//
//		        // 다음 바이트 수신 준비
//		        HAL_UART_Receive_IT(&huart4, &rxByte, 1);
//
//
//

	// HAL_UART_Receive_IT(&huart4, &data, 1);

//	 printf("%d -- %c \r\n", data, data);
	 switch (RxRX) {
	 case '0':

	 break;

	 case 'z':
		 linear_motor_GO(go_time);
	 	 break;
	 case 'x':
			linear_go_flag=1;
		 linear_motor_BACK(back_time);
	 	 break;
	 case 'Q':
		 z_axis_UP(400 * 6, ball_screw_pulse_cycle);
	 	 break;
	 case 'E':
		 z_axis_DOWN(400 * 6 + 100, ball_screw_pulse_cycle);
	 	 break;
	 case 'q':
		 z_axis_UP(ball_step, ball_screw_pulse_cycle);
	 	 break;
	 case 'e':
		 z_axis_DOWN(ball_step, ball_screw_pulse_cycle);
	 	 break;

	 case 'R':
		 FALSE_Init();
		 down_part_UP(3000, shaft_pulse_cycle);
	 	 break;
	 case 'T':
		 FALSE_Init();
		 down_part_DOWN(3000, shaft_pulse_cycle);
	 	 break;
	 case 'r':
		 FALSE_Init();
		 down_part_UP(downpart_step, shaft_pulse_cycle);
	 	 break;
	 case 't':
		 FALSE_Init();
		 		down_part_DOWN(downpart_step, shaft_pulse_cycle);
	 	 	 break;

	 }

}

/* USER CODE END 4 */

void Error_Handler(void)
{
	__disable_irq();
	while (1) {
	}
}
